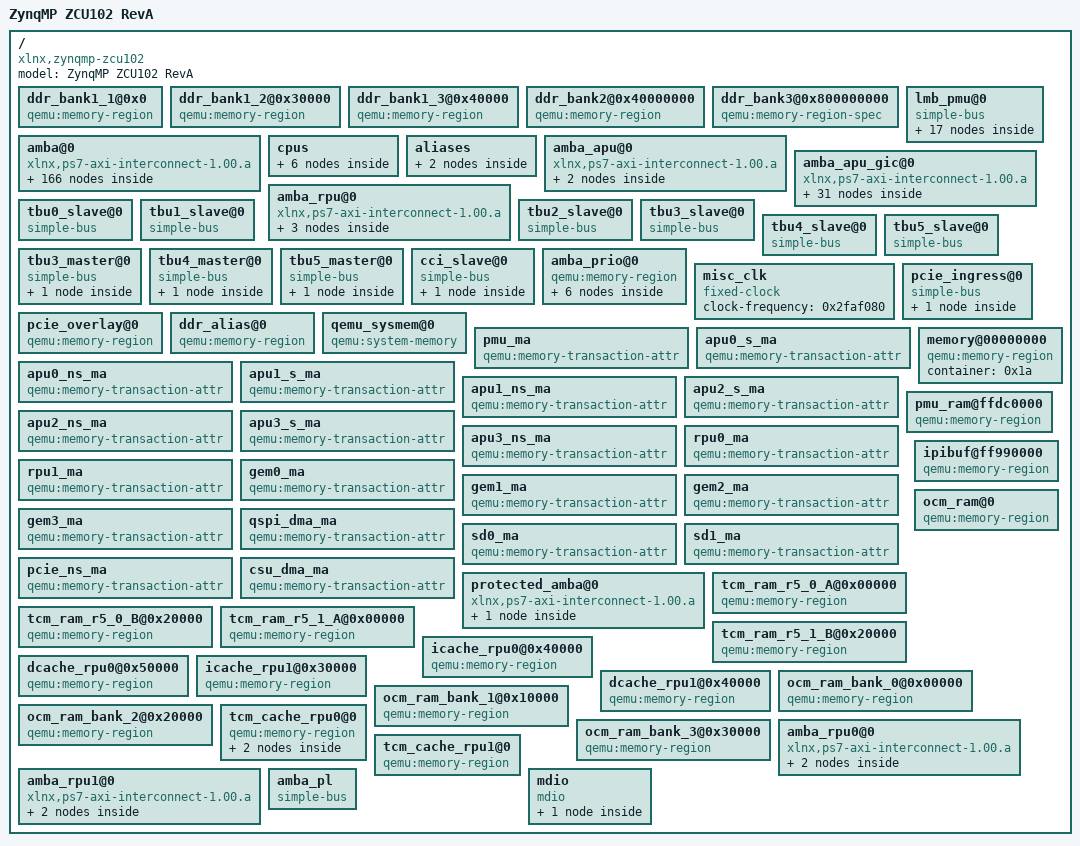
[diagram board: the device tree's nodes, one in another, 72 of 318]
/dts-v1/;

/ {
	#address-cells = <0x02>;
	#size-cells = <0x01>;
	model = "ZynqMP ZCU102 RevA";
	compatible = "xlnx,zynqmp-zcu102\0xlnx,zynqmp";

	ddr_bank1_1@0x0 {
		compatible = "qemu:memory-region";
		container = <0x01>;
		qemu,ram = <0x01>;
		reg = <0x00 0x00 0x30000>;
	};

	ddr_bank1_2@0x30000 {
		compatible = "qemu:memory-region";
		container = <0x01>;
		qemu,ram = <0x01>;
		reg = <0x00 0x30000 0x10000>;
		phandle = <0x74>;
	};

	ddr_bank1_3@0x40000 {
		compatible = "qemu:memory-region";
		container = <0x01>;
		qemu,ram = <0x01>;
		reg = <0x00 0x40000 0x3ffc0000>;
	};

	ddr_bank2@0x40000000 {
		compatible = "qemu:memory-region";
		container = <0x01>;
		qemu,ram = <0x01>;
		reg = <0x00 0x40000000 0x40000000>;
	};

	ddr_bank3@0x800000000 {
		compatible = "qemu:memory-region-spec";
		container = <0x01>;
		qemu,ram = <0x01>;
		reg = <0x08 0x00 0x08 0x00>;
	};

	amba@0 {
		#interrupt-cells = <0x01>;
		compatible = "xlnx,ps7-axi-interconnect-1.00.a\0simple-bus";
		ranges;
		interrupt-map-mask = <0x00 0x00 0xffff>;
		interrupt-map = <0x00 0x00 0x08 0x02 0x00 0x08 0x04 0x00 0x00 0x09 0x02 0x00 0x09 0x04 0x00 0x00 0x0a 0x02 0x00 0x0a 0x04 0x00 0x00 0x0b 0x02 0x00 0x0b 0x04 0x00 0x00 0x0b 0x02 0x00 0x0b 0x04 0x00 0x00 0x0b 0x02 0x00 0x0b 0x04 0x00 0x00 0x0b 0x02 0x00 0x0b 0x04 0x00 0x00 0x0b 0x02 0x00 0x0b 0x04 0x00 0x00 0x0b 0x02 0x00 0x0b 0x04 0x00 0x00 0x0b 0x02 0x00 0x0b 0x04 0x00 0x00 0x0b 0x02 0x00 0x0b 0x04 0x00 0x00 0x0b 0x02 0x00 0x0b 0x04 0x00 0x00 0x0b 0x02 0x00 0x0b 0x04 0x00 0x00 0x0b 0x02 0x00 0x0b 0x04 0x00 0x00 0x0b 0x02 0x00 0x0b 0x04 0x00 0x00 0x0b 0x02 0x00 0x0b 0x04 0x00 0x00 0x0b 0x02 0x00 0x0b 0x04 0x00 0x00 0x0c 0x02 0x00 0x0c 0x04 0x00 0x00 0x0d 0x02 0x00 0x0d 0x04 0x00 0x00 0x0e 0x02 0x00 0x0e 0x04 0x00 0x00 0x0f 0x02 0x00 0x0f 0x04 0x00 0x00 0x10 0x02 0x00 0x10 0x04 0x00 0x00 0x11 0x02 0x00 0x11 0x04 0x00 0x00 0x12 0x02 0x00 0x12 0x04 0x00 0x00 0x13 0x02 0x00 0x13 0x04 0x00 0x00 0x14 0x02 0x00 0x14 0x04 0x00 0x00 0x15 0x02 0x00 0x15 0x04 0x00 0x00 0x16 0x02 0x00 0x16 0x04 0x00 0x00 0x17 0x02 0x00 0x17 0x04 0x00 0x00 0x18 0x02 0x00 0x18 0x04 0x00 0x00 0x19 0x02 0x00 0x19 0x04 0x00 0x00 0x19 0x02 0x00 0x19 0x04 0x00 0x00 0x1a 0x02 0x00 0x1a 0x04 0x00 0x00 0x1b 0x02 0x00 0x1b 0x04 0x00 0x00 0x1c 0x02 0x00 0x1c 0x04 0x00 0x00 0x1d 0x02 0x00 0x1d 0x04 0x00 0x00 0x1e 0x02 0x00 0x1e 0x04 0x00 0x00 0x1f 0x02 0x00 0x1f 0x04 0x00 0x00 0x20 0x02 0x00 0x20 0x04 0x00 0x00 0x21 0x02 0x00 0x21 0x04 0x00 0x00 0x22 0x02 0x00 0x22 0x04 0x00 0x00 0x23 0x02 0x00 0x23 0x04 0x00 0x00 0x24 0x02 0x00 0x24 0x04 0x00 0x00 0x25 0x02 0x00 0x25 0x04 0x00 0x00 0x26 0x02 0x00 0x26 0x04 0x00 0x00 0x27 0x02 0x00 0x27 0x04 0x00 0x00 0x28 0x02 0x00 0x28 0x04 0x00 0x00 0x29 0x02 0x00 0x29 0x04 0x00 0x00 0x2a 0x02 0x00 0x2a 0x04 0x00 0x00 0x2b 0x02 0x00 0x2b 0x04 0x00 0x00 0x2c 0x02 0x00 0x2c 0x04 0x00 0x00 0x2d 0x02 0x00 0x2d 0x04 0x00 0x00 0x2e 0x02 0x00 0x2e 0x04 0x00 0x00 0x2f 0x02 0x00 0x2f 0x04 0x00 0x00 0x30 0x02 0x00 0x30 0x04 0x00 0x00 0x31 0x02 0x00 0x31 0x04 0x00 0x00 0x32 0x02 0x00 0x32 0x04 0x00 0x00 0x33 0x02 0x00 0x33 0x04 0x00 0x00 0x34 0x02 0x00 0x34 0x04 0x00 0x00 0x35 0x02 0x00 0x35 0x04 0x00 0x00 0x36 0x02 0x00 0x36 0x04 0x00 0x00 0x37 0x02 0x00 0x37 0x04 0x00 0x00 0x38 0x02 0x00 0x38 0x04 0x00 0x00 0x39 0x02 0x00 0x39 0x04 0x00 0x00 0x3a 0x02 0x00 0x3a 0x04 0x00 0x00 0x3b 0x02 0x00 0x3b 0x04 0x00 0x00 0x3c 0x02 0x00 0x3c 0x04 0x00 0x00 0x3d 0x02 0x00 0x3d 0x04 0x00 0x00 0x3e 0x02 0x00 0x3e 0x04 0x00 0x00 0x3f 0x02 0x00 0x3f 0x04 0x00 0x00 0x40 0x02 0x00 0x40 0x04 0x00 0x00 0x41 0x02 0x00 0x41 0x04 0x00 0x00 0x42 0x02 0x00 0x42 0x04 0x00 0x00 0x43 0x02 0x00 0x43 0x04 0x00 0x00 0x44 0x02 0x00 0x44 0x04 0x00 0x00 0x45 0x02 0x00 0x45 0x04 0x00 0x00 0x46 0x02 0x00 0x46 0x04 0x00 0x00 0x47 0x02 0x00 0x47 0x04 0x00 0x00 0x48 0x02 0x00 0x48 0x04 0x00 0x00 0x49 0x02 0x00 0x49 0x04 0x00 0x00 0x4a 0x02 0x00 0x4a 0x04 0x00 0x00 0x4b 0x02 0x00 0x4b 0x04 0x00 0x00 0x4c 0x02 0x00 0x4c 0x04 0x00 0x00 0x4d 0x02 0x00 0x4d 0x04 0x00 0x00 0x4e 0x02 0x00 0x4e 0x04 0x00 0x00 0x4f 0x02 0x00 0x4f 0x04 0x00 0x00 0x50 0x02 0x00 0x50 0x04 0x00 0x00 0x51 0x02 0x00 0x51 0x04 0x00 0x00 0x52 0x02 0x00 0x52 0x04 0x00 0x00 0x53 0x02 0x00 0x53 0x04 0x00 0x00 0x54 0x02 0x00 0x54 0x04 0x00 0x00 0x55 0x02 0x00 0x55 0x04 0x00 0x00 0x56 0x02 0x00 0x56 0x04 0x00 0x00 0x57 0x02 0x00 0x57 0x04 0x00 0x00 0x58 0x02 0x00 0x58 0x04 0x00 0x00 0x58 0x02 0x00 0x58 0x04 0x00 0x00 0x59 0x02 0x00 0x59 0x04 0x00 0x00 0x5a 0x02 0x00 0x5a 0x04 0x00 0x00 0x5b 0x02 0x00 0x5b 0x04 0x00 0x00 0x5c 0x02 0x00 0x5c 0x04 0x00 0x00 0x5d 0x02 0x00 0x5d 0x04 0x00 0x00 0x5e 0x02 0x00 0x5e 0x04 0x00 0x00 0x5f 0x02 0x00 0x5f 0x04 0x00 0x00 0x60 0x02 0x00 0x60 0x04 0x00 0x00 0x68 0x02 0x00 0x68 0x04 0x00 0x00 0x69 0x02 0x00 0x69 0x04 0x00 0x00 0x6a 0x02 0x00 0x6a 0x04 0x00 0x00 0x6b 0x02 0x00 0x6b 0x04 0x00 0x00 0x6c 0x02 0x00 0x6c 0x04 0x00 0x00 0x6d 0x02 0x00 0x6d 0x04 0x00 0x00 0x6e 0x02 0x00 0x6e 0x04 0x00 0x00 0x6f 0x02 0x00 0x6f 0x04 0x00 0x00 0x70 0x02 0x00 0x70 0x04 0x00 0x00 0x71 0x02 0x00 0x71 0x04 0x00 0x00 0x72 0x02 0x00 0x72 0x04 0x00 0x00 0x73 0x02 0x00 0x73 0x04 0x00 0x00 0x74 0x02 0x00 0x74 0x04 0x00 0x00 0x75 0x02 0x00 0x75 0x04 0x00 0x00 0x76 0x02 0x00 0x76 0x04 0x00 0x00 0x77 0x02 0x00 0x77 0x04 0x00 0x00 0x78 0x02 0x00 0x78 0x04 0x00 0x00 0x78 0x02 0x00 0x78 0x04 0x00 0x00 0x78 0x02 0x00 0x78 0x04 0x00 0x00 0x78 0x02 0x00 0x78 0x04 0x00 0x00 0x78 0x02 0x00 0x78 0x04 0x00 0x00 0x78 0x02 0x00 0x78 0x04 0x00 0x00 0x78 0x02 0x00 0x78 0x04 0x00 0x00 0x78 0x02 0x00 0x78 0x04 0x00 0x00 0x78 0x02 0x00 0x78 0x04 0x00 0x00 0x78 0x02 0x00 0x78 0x04 0x00 0x00 0x78 0x02 0x00 0x78 0x04 0x00 0x00 0x79 0x02 0x00 0x79 0x04 0x00 0x00 0x7a 0x02 0x00 0x7a 0x04 0x00 0x00 0x7b 0x02 0x00 0x7b 0x04 0x00 0x00 0x7b 0x02 0x00 0x7b 0x04 0x00 0x00 0x7c 0x02 0x00 0x7c 0x04 0x00 0x00 0x7d 0x02 0x00 0x7d 0x04 0x00 0x00 0x7e 0x02 0x00 0x7e 0x04 0x00 0x00 0x7f 0x02 0x00 0x7f 0x04 0x00 0x00 0x80 0x02 0x00 0x80 0x04 0x00 0x00 0x81 0x02 0x00 0x81 0x04 0x00 0x00 0x82 0x02 0x00 0x82 0x04 0x00 0x00 0x83 0x02 0x00 0x83 0x04 0x00 0x00 0x84 0x02 0x00 0x84 0x04 0x00 0x00 0x85 0x02 0x00 0x85 0x04 0x00 0x00 0x86 0x02 0x00 0x86 0x04 0x00 0x00 0x86 0x02 0x00 0x86 0x04 0x00 0x00 0x86 0x02 0x00 0x86 0x04 0x00 0x00 0x86 0x02 0x00 0x86 0x04 0x00 0x00 0x86 0x02 0x00 0x86 0x04 0x00 0x00 0x86 0x02 0x00 0x86 0x04 0x00 0x00 0x86 0x02 0x00 0x86 0x04 0x00 0x00 0x87 0x02 0x00 0x87 0x04 0x00 0x00 0x88 0x02 0x00 0x88 0x04 0x00 0x00 0x89 0x02 0x00 0x89 0x04 0x00 0x00 0x8a 0x02 0x00 0x8a 0x04 0x00 0x00 0x8b 0x02 0x00 0x8b 0x04 0x00 0x00 0x8c 0x02 0x00 0x8c 0x04 0x00 0x00 0x8d 0x02 0x00 0x8d 0x04 0x00 0x00 0x8e 0x02 0x00 0x8e 0x04 0x00 0x00 0x8f 0x02 0x00 0x8f 0x04 0x00 0x00 0x90 0x02 0x00 0x90 0x04 0x00 0x00 0x91 0x02 0x00 0x91 0x04 0x00 0x00 0x92 0x02 0x00 0x92 0x04 0x00 0x00 0x93 0x02 0x00 0x93 0x04 0x00 0x00 0x94 0x02 0x00 0x94 0x04 0x00 0x00 0x95 0x02 0x00 0x95 0x04 0x00 0x00 0x96 0x02 0x00 0x96 0x04 0x00 0x00 0x97 0x02 0x00 0x97 0x04 0x00 0x00 0x98 0x02 0x00 0x98 0x04 0x00 0x00 0x99 0x02 0x00 0x99 0x04 0x00 0x00 0x9a 0x02 0x00 0x9a 0x04 0x00 0x00 0x9b 0x02 0x00 0x9b 0x04 0x00 0x00 0x08 0x03 0x00 0x08 0x04 0x00 0x00 0x09 0x03 0x00 0x09 0x04 0x00 0x00 0x0a 0x03 0x00 0x0a 0x04 0x00 0x00 0x0b 0x03 0x00 0x0b 0x04 0x00 0x00 0x0b 0x03 0x00 0x0b 0x04 0x00 0x00 0x0b 0x03 0x00 0x0b 0x04 0x00 0x00 0x0b 0x03 0x00 0x0b 0x04 0x00 0x00 0x0b 0x03 0x00 0x0b 0x04 0x00 0x00 0x0b 0x03 0x00 0x0b 0x04 0x00 0x00 0x0b 0x03 0x00 0x0b 0x04 0x00 0x00 0x0b 0x03 0x00 0x0b 0x04 0x00 0x00 0x0b 0x03 0x00 0x0b 0x04 0x00 0x00 0x0b 0x03 0x00 0x0b 0x04 0x00 0x00 0x0b 0x03 0x00 0x0b 0x04 0x00 0x00 0x0b 0x03 0x00 0x0b 0x04 0x00 0x00 0x0b 0x03 0x00 0x0b 0x04 0x00 0x00 0x0b 0x03 0x00 0x0b 0x04 0x00 0x00 0x0c 0x03 0x00 0x0c 0x04 0x00 0x00 0x0d 0x03 0x00 0x0d 0x04 0x00 0x00 0x0e 0x03 0x00 0x0e 0x04 0x00 0x00 0x0f 0x03 0x00 0x0f 0x04 0x00 0x00 0x10 0x03 0x00 0x10 0x04 0x00 0x00 0x11 0x03 0x00 0x11 0x04 0x00 0x00 0x12 0x03 0x00 0x12 0x04 0x00 0x00 0x13 0x03 0x00 0x13 0x04 0x00 0x00 0x14 0x03 0x00 0x14 0x04 0x00 0x00 0x15 0x03 0x00 0x15 0x04 0x00 0x00 0x16 0x03 0x00 0x16 0x04 0x00 0x00 0x17 0x03 0x00 0x17 0x04 0x00 0x00 0x18 0x03 0x00 0x18 0x04 0x00 0x00 0x19 0x03 0x00 0x19 0x04 0x00 0x00 0x19 0x03 0x00 0x19 0x04 0x00 0x00 0x1a 0x03 0x00 0x1a 0x04 0x00 0x00 0x1b 0x03 0x00 0x1b 0x04 0x00 0x00 0x1c 0x03 0x00 0x1c 0x04 0x00 0x00 0x1d 0x03 0x00 0x1d 0x04 0x00 0x00 0x1e 0x03 0x00 0x1e 0x04 0x00 0x00 0x1f 0x03 0x00 0x1f 0x04 0x00 0x00 0x20 0x03 0x00 0x20 0x04 0x00 0x00 0x21 0x03 0x00 0x21 0x04 0x00 0x00 0x22 0x03 0x00 0x22 0x04 0x00 0x00 0x23 0x03 0x00 0x23 0x04 0x00 0x00 0x24 0x03 0x00 0x24 0x04 0x00 0x00 0x25 0x03 0x00 0x25 0x04 0x00 0x00 0x26 0x03 0x00 0x26 0x04 0x00 0x00 0x27 0x03 0x00 0x27 0x04 0x00 0x00 0x28 0x03 0x00 0x28 0x04 0x00 0x00 0x29 0x03 0x00 0x29 0x04 0x00 0x00 0x2a 0x03 0x00 0x2a 0x04 0x00 0x00 0x2b 0x03 0x00 0x2b 0x04 0x00 0x00 0x2c 0x03 0x00 0x2c 0x04 0x00 0x00 0x2d 0x03 0x00 0x2d 0x04 0x00 0x00 0x2e 0x03 0x00 0x2e 0x04 0x00 0x00 0x2f 0x03 0x00 0x2f 0x04 0x00 0x00 0x30 0x03 0x00 0x30 0x04 0x00 0x00 0x31 0x03 0x00 0x31 0x04 0x00 0x00 0x32 0x03 0x00 0x32 0x04 0x00 0x00 0x33 0x03 0x00 0x33 0x04 0x00 0x00 0x34 0x03 0x00 0x34 0x04 0x00 0x00 0x35 0x03 0x00 0x35 0x04 0x00 0x00 0x36 0x03 0x00 0x36 0x04 0x00 0x00 0x37 0x03 0x00 0x37 0x04 0x00 0x00 0x38 0x03 0x00 0x38 0x04 0x00 0x00 0x39 0x03 0x00 0x39 0x04 0x00 0x00 0x3a 0x03 0x00 0x3a 0x04 0x00 0x00 0x3b 0x03 0x00 0x3b 0x04 0x00 0x00 0x3c 0x03 0x00 0x3c 0x04 0x00 0x00 0x3d 0x03 0x00 0x3d 0x04 0x00 0x00 0x3e 0x03 0x00 0x3e 0x04 0x00 0x00 0x3f 0x03 0x00 0x3f 0x04 0x00 0x00 0x40 0x03 0x00 0x40 0x04 0x00 0x00 0x41 0x03 0x00 0x41 0x04 0x00 0x00 0x42 0x03 0x00 0x42 0x04 0x00 0x00 0x43 0x03 0x00 0x43 0x04 0x00 0x00 0x44 0x03 0x00 0x44 0x04 0x00 0x00 0x45 0x03 0x00 0x45 0x04 0x00 0x00 0x46 0x03 0x00 0x46 0x04 0x00 0x00 0x47 0x03 0x00 0x47 0x04 0x00 0x00 0x48 0x03 0x00 0x48 0x04 0x00 0x00 0x49 0x03 0x00 0x49 0x04 0x00 0x00 0x4a 0x03 0x00 0x4a 0x04 0x00 0x00 0x4b 0x03 0x00 0x4b 0x04 0x00 0x00 0x4c 0x03 0x00 0x4c 0x04 0x00 0x00 0x4d 0x03 0x00 0x4d 0x04 0x00 0x00 0x4e 0x03 0x00 0x4e 0x04 0x00 0x00 0x4f 0x03 0x00 0x4f 0x04 0x00 0x00 0x50 0x03 0x00 0x50 0x04 0x00 0x00 0x51 0x03 0x00 0x51 0x04 0x00 0x00 0x52 0x03 0x00 0x52 0x04 0x00 0x00 0x53 0x03 0x00 0x53 0x04 0x00 0x00 0x54 0x03 0x00 0x54 0x04 0x00 0x00 0x55 0x03 0x00 0x55 0x04 0x00 0x00 0x56 0x03 0x00 0x56 0x04 0x00 0x00 0x57 0x03 0x00 0x57 0x04 0x00 0x00 0x58 0x03 0x00 0x58 0x04 0x00 0x00 0x58 0x03 0x00 0x58 0x04 0x00 0x00 0x59 0x03 0x00 0x59 0x04 0x00 0x00 0x5a 0x03 0x00 0x5a 0x04 0x00 0x00 0x5b 0x03 0x00 0x5b 0x04 0x00 0x00 0x5c 0x03 0x00 0x5c 0x04 0x00 0x00 0x5d 0x03 0x00 0x5d 0x04 0x00 0x00 0x5e 0x03 0x00 0x5e 0x04 0x00 0x00 0x5f 0x03 0x00 0x5f 0x04 0x00 0x00 0x60 0x03 0x00 0x60 0x04 0x00 0x00 0x68 0x03 0x00 0x68 0x04 0x00 0x00 0x69 0x03 0x00 0x69 0x04 0x00 0x00 0x6a 0x03 0x00 0x6a 0x04 0x00 0x00 0x6b 0x03 0x00 0x6b 0x04 0x00 0x00 0x6c 0x03 0x00 0x6c 0x04 0x00 0x00 0x6d 0x03 0x00 0x6d 0x04 0x00 0x00 0x6e 0x03 0x00 0x6e 0x04 0x00 0x00 0x6f 0x03 0x00 0x6f 0x04 0x00 0x00 0x70 0x03 0x00 0x70 0x04 0x00 0x00 0x71 0x03 0x00 0x71 0x04 0x00 0x00 0x72 0x03 0x00 0x72 0x04 0x00 0x00 0x73 0x03 0x00 0x73 0x04 0x00 0x00 0x74 0x03 0x00 0x74 0x04 0x00 0x00 0x75 0x03 0x00 0x75 0x04 0x00 0x00 0x76 0x03 0x00 0x76 0x04 0x00 0x00 0x77 0x03 0x00 0x77 0x04 0x00 0x00 0x78 0x03 0x00 0x78 0x04 0x00 0x00 0x78 0x03 0x00 0x78 0x04 0x00 0x00 0x78 0x03 0x00 0x78 0x04 0x00 0x00 0x78 0x03 0x00 0x78 0x04 0x00 0x00 0x78 0x03 0x00 0x78 0x04 0x00 0x00 0x78 0x03 0x00 0x78 0x04 0x00 0x00 0x78 0x03 0x00 0x78 0x04 0x00 0x00 0x78 0x03 0x00 0x78 0x04 0x00 0x00 0x78 0x03 0x00 0x78 0x04 0x00 0x00 0x78 0x03 0x00 0x78 0x04 0x00 0x00 0x78 0x03 0x00 0x78 0x04 0x00 0x00 0x79 0x03 0x00 0x79 0x04 0x00 0x00 0x7a 0x03 0x00 0x7a 0x04 0x00 0x00 0x7b 0x03 0x00 0x7b 0x04 0x00 0x00 0x7b 0x03 0x00 0x7b 0x04 0x00 0x00 0x7c 0x03 0x00 0x7c 0x04 0x00 0x00 0x7d 0x03 0x00 0x7d 0x04 0x00 0x00 0x7e 0x03 0x00 0x7e 0x04 0x00 0x00 0x7f 0x03 0x00 0x7f 0x04 0x00 0x00 0x80 0x03 0x00 0x80 0x04 0x00 0x00 0x81 0x03 0x00 0x81 0x04 0x00 0x00 0x82 0x03 0x00 0x82 0x04 0x00 0x00 0x83 0x03 0x00 0x83 0x04 0x00 0x00 0x84 0x03 0x00 0x84 0x04 0x00 0x00 0x85 0x03 0x00 0x85 0x04 0x00 0x00 0x86 0x03 0x00 0x86 0x04 0x00 0x00 0x86 0x03 0x00 0x86 0x04 0x00 0x00 0x86 0x03 0x00 0x86 0x04 0x00 0x00 0x86 0x03 0x00 0x86 0x04 0x00 0x00 0x86 0x03 0x00 0x86 0x04 0x00 0x00 0x86 0x03 0x00 0x86 0x04 0x00 0x00 0x86 0x03 0x00 0x86 0x04 0x00 0x00 0x87 0x03 0x00 0x87 0x04 0x00 0x00 0x88 0x03 0x00 0x88 0x04 0x00 0x00 0x89 0x03 0x00 0x89 0x04 0x00 0x00 0x8a 0x03 0x00 0x8a 0x04 0x00 0x00 0x8b 0x03 0x00 0x8b 0x04 0x00 0x00 0x8c 0x03 0x00 0x8c 0x04 0x00 0x00 0x8d 0x03 0x00 0x8d 0x04 0x00 0x00 0x8e 0x03 0x00 0x8e 0x04 0x00 0x00 0x8f 0x03 0x00 0x8f 0x04 0x00 0x00 0x90 0x03 0x00 0x90 0x04 0x00 0x00 0x91 0x03 0x00 0x91 0x04 0x00 0x00 0x92 0x03 0x00 0x92 0x04 0x00 0x00 0x93 0x03 0x00 0x93 0x04 0x00 0x00 0x94 0x03 0x00 0x94 0x04 0x00 0x00 0x95 0x03 0x00 0x95 0x04 0x00 0x00 0x96 0x03 0x00 0x96 0x04 0x00 0x00 0x97 0x03 0x00 0x97 0x04 0x00 0x00 0x98 0x03 0x00 0x98 0x04 0x00 0x00 0x99 0x03 0x00 0x99 0x04 0x00 0x00 0x9a 0x03 0x00 0x9a 0x04 0x00 0x00 0x9b 0x03 0x00 0x9b 0x04>;
		#address-cells = <0x02>;
		#size-cells = <0x01>;
		phandle = <0x1a>;

		apu@0xFD5C0000 {
			compatible = "xlnx,apu";
			#gpio-cells = <0x01>;
			reg = <0x00 0xfd5c0000 0x1000>;
			cpu0 = <0x04>;
			cpu1 = <0x05>;
			cpu2 = <0x06>;
			cpu3 = <0x07>;
		};

		rpu_control@0xFF9A0000 {
			#gpio-cells = <0x01>;
			compatible = "xlnx,rpu-control";
			reg = <0x00 0xff9a0000 0x400>;
			gpio-controller;
			atcm1-for-rpu0 = <0x08>;
			btcm1-for-rpu0 = <0x09>;
			icache-for-rpu1 = <0x0a>;
			dcache-for-rpu1 = <0x0b>;
			gic-for-rpu = <0x03>;
			gpios = <0x0c 0x06 0x0c 0x07>;
			ddr-mem-for-rpu = <0x0d>;
			phandle = <0x6c>;
		};

		pmu_global@0xFFD80000 {
			interrupt-parent = <0x0e>;
			interrupts = <0x17 0x00 0x18 0x00 0x1a 0x00 0x1b 0x00 0x1c 0x00 0x1d 0x00>;
			compatible = "xlnx,pmu_global";
			reg = <0x00 0xffd80000 0x40000>;
			gpio-controller;
			#gpio-cells = <0x01>;
			num-gpios = <0x1a>;
			ignore-pwr-req = <0x01>;
			phandle = <0x0c>;
		};

		apu_ipi@0xFF300000 {
			compatible = "xlnx,zynqmp_ipi";
			gpio-controller;
			#gpio-cells = <0x02>;
			interrupts = <0x00>;
			interrupt-map = <0x00 0x00 0x00 0x02 0x00 0x23 0x04 0x00 0x00 0x00 0x03 0x00 0x23 0x04>;
			interrupt-map-mask = <0x00 0x00 0x00 0x00>;
			reg = <0x00 0xff300000 0x1000>;
			num-gpios = <0x40>;
			interrupt-gpios = <0x0f 0x00 0x00 0x10 0x00 0x00 0x11 0x00 0x00 0x12 0x00 0x00 0x13 0x00 0x00 0x14 0x00 0x00 0x15 0x00 0x00 0x16 0x00 0x00 0x17 0x00 0x00 0x18 0x00 0x00 0x19 0x00 0x00>;
			gpios = <0x0f 0x20 0x00 0x10 0x20 0x00 0x11 0x20 0x00 0x12 0x20 0x00 0x13 0x20 0x00 0x14 0x20 0x00 0x15 0x20 0x00 0x16 0x20 0x00 0x17 0x20 0x00 0x18 0x20 0x00 0x19 0x20 0x00>;
			phandle = <0x0f>;
		};

		rpu_0_ipi@0xFF310000 {
			compatible = "xlnx,zynqmp_ipi";
			gpio-controller;
			#gpio-cells = <0x02>;
			interrupts = <0x00>;
			interrupt-map = <0x00 0x00 0x00 0x02 0x00 0x21 0x04 0x00 0x00 0x00 0x03 0x00 0x21 0x04>;
			interrupt-map-mask = <0x00 0x00 0x00 0x00>;
			reg = <0x00 0xff310000 0x1000>;
			num-gpios = <0x40>;
			interrupt-gpios = <0x0f 0x08 0x00 0x10 0x08 0x00 0x11 0x08 0x00 0x12 0x08 0x00 0x13 0x08 0x00 0x14 0x08 0x00 0x15 0x08 0x00 0x16 0x08 0x00 0x17 0x08 0x00 0x18 0x08 0x00 0x19 0x08 0x00>;
			gpios = <0x0f 0x28 0x00 0x10 0x28 0x00 0x11 0x28 0x00 0x12 0x28 0x00 0x13 0x28 0x00 0x14 0x28 0x00 0x15 0x28 0x00 0x16 0x28 0x00 0x17 0x28 0x00 0x18 0x28 0x00 0x19 0x28 0x00>;
			phandle = <0x10>;
		};

		rpu_1_ipi@0xFF320000 {
			compatible = "xlnx,zynqmp_ipi";
			gpio-controller;
			#gpio-cells = <0x02>;
			interrupts = <0x00>;
			interrupt-map = <0x00 0x00 0x00 0x02 0x00 0x22 0x04 0x00 0x00 0x00 0x03 0x00 0x22 0x04>;
			interrupt-map-mask = <0x00 0x00 0x00 0x00>;
			reg = <0x00 0xff320000 0x1000>;
			num-gpios = <0x40>;
			interrupt-gpios = <0x0f 0x09 0x00 0x10 0x09 0x00 0x11 0x09 0x00 0x12 0x09 0x00 0x13 0x09 0x00 0x14 0x09 0x00 0x15 0x09 0x00 0x16 0x09 0x00 0x17 0x09 0x00 0x18 0x09 0x00 0x19 0x09 0x00>;
			gpios = <0x0f 0x29 0x00 0x10 0x29 0x00 0x11 0x29 0x00 0x12 0x29 0x00 0x13 0x29 0x00 0x14 0x29 0x00 0x15 0x29 0x00 0x16 0x29 0x00 0x17 0x29 0x00 0x18 0x29 0x00 0x19 0x29 0x00>;
			phandle = <0x11>;
		};

		pmu_0_ipi@0xFF330000 {
			compatible = "xlnx,zynqmp_ipi";
			gpio-controller;
			#gpio-cells = <0x02>;
			interrupt-parent = <0x0e>;
			interrupts = <0x13 0x00>;
			reg = <0x00 0xff330000 0x1000>;
			num-gpios = <0x40>;
			interrupt-gpios = <0x0f 0x10 0x00 0x10 0x10 0x00 0x11 0x10 0x00 0x12 0x10 0x00 0x13 0x10 0x00 0x14 0x10 0x00 0x15 0x10 0x00 0x16 0x10 0x00 0x17 0x10 0x00 0x18 0x10 0x00 0x19 0x10 0x00>;
			gpios = <0x0f 0x30 0x00 0x10 0x30 0x00 0x11 0x30 0x00 0x12 0x30 0x00 0x13 0x30 0x00 0x14 0x30 0x00 0x15 0x30 0x00 0x16 0x30 0x00 0x17 0x30 0x00 0x18 0x30 0x00 0x19 0x30 0x00>;
			phandle = <0x12>;
		};

		pmu_1_ipi@0xFF331000 {
			compatible = "xlnx,zynqmp_ipi";
			gpio-controller;
			#gpio-cells = <0x02>;
			interrupt-parent = <0x0e>;
			interrupts = <0x14 0x00>;
			reg = <0x00 0xff331000 0x1000>;
			num-gpios = <0x40>;
			interrupt-gpios = <0x0f 0x11 0x00 0x10 0x11 0x00 0x11 0x11 0x00 0x12 0x11 0x00 0x13 0x11 0x00 0x14 0x11 0x00 0x15 0x11 0x00 0x16 0x11 0x00 0x17 0x11 0x00 0x18 0x11 0x00 0x19 0x11 0x00>;
			gpios = <0x0f 0x31 0x00 0x10 0x31 0x00 0x11 0x31 0x00 0x12 0x31 0x00 0x13 0x31 0x00 0x14 0x31 0x00 0x15 0x31 0x00 0x16 0x31 0x00 0x17 0x31 0x00 0x18 0x31 0x00 0x19 0x31 0x00>;
			phandle = <0x13>;
		};

		pmu_2_ipi@0xFF332000 {
			compatible = "xlnx,zynqmp_ipi";
			gpio-controller;
			#gpio-cells = <0x02>;
			interrupt-parent = <0x0e>;
			interrupts = <0x15 0x00>;
			reg = <0x00 0xff332000 0x1000>;
			num-gpios = <0x40>;
			interrupt-gpios = <0x0f 0x12 0x00 0x10 0x12 0x00 0x11 0x12 0x00 0x12 0x12 0x00 0x13 0x12 0x00 0x14 0x12 0x00 0x15 0x12 0x00 0x16 0x12 0x00 0x17 0x12 0x00 0x18 0x12 0x00 0x19 0x12 0x00>;
			gpios = <0x0f 0x32 0x00 0x10 0x32 0x00 0x11 0x32 0x00 0x12 0x32 0x00 0x13 0x32 0x00 0x14 0x32 0x00 0x15 0x32 0x00 0x16 0x32 0x00 0x17 0x32 0x00 0x18 0x32 0x00 0x19 0x32 0x00>;
			phandle = <0x14>;
		};

		pmu_3_ipi@0xFF333000 {
			compatible = "xlnx,zynqmp_ipi";
			gpio-controller;
			#gpio-cells = <0x02>;
			interrupt-parent = <0x0e>;
			interrupts = <0x16 0x00>;
			reg = <0x00 0xff333000 0x1000>;
			num-gpios = <0x40>;
			interrupt-gpios = <0x0f 0x13 0x00 0x10 0x13 0x00 0x11 0x13 0x00 0x12 0x13 0x00 0x13 0x13 0x00 0x14 0x13 0x00 0x15 0x13 0x00 0x16 0x13 0x00 0x17 0x13 0x00 0x18 0x13 0x00 0x19 0x13 0x00>;
			gpios = <0x0f 0x33 0x00 0x10 0x33 0x00 0x11 0x33 0x00 0x12 0x33 0x00 0x13 0x33 0x00 0x14 0x33 0x00 0x15 0x33 0x00 0x16 0x33 0x00 0x17 0x33 0x00 0x18 0x33 0x00 0x19 0x33 0x00>;
			phandle = <0x15>;
		};

		pl_0_ipi@0xFF340000 {
			compatible = "xlnx,zynqmp_ipi";
			gpio-controller;
			#gpio-cells = <0x02>;
			interrupts = <0x00>;
			interrupt-map = <0x00 0x00 0x00 0x02 0x00 0x1d 0x04 0x00 0x00 0x00 0x03 0x00 0x1d 0x04>;
			interrupt-map-mask = <0x00 0x00 0x00 0x00>;
			reg = <0x00 0xff340000 0x1000>;
			num-gpios = <0x40>;
			interrupt-gpios = <0x0f 0x18 0x00 0x10 0x18 0x00 0x11 0x18 0x00 0x12 0x18 0x00 0x13 0x18 0x00 0x14 0x18 0x00 0x15 0x18 0x00 0x16 0x18 0x00 0x17 0x18 0x00 0x18 0x18 0x00 0x19 0x18 0x00>;
			gpios = <0x0f 0x34 0x00 0x10 0x34 0x00 0x11 0x34 0x00 0x12 0x34 0x00 0x13 0x34 0x00 0x14 0x34 0x00 0x15 0x34 0x00 0x16 0x34 0x00 0x17 0x34 0x00 0x18 0x34 0x00 0x19 0x34 0x00>;
			phandle = <0x16>;
		};

		pl_1_ipi@0xFF350000 {
			compatible = "xlnx,zynqmp_ipi";
			gpio-controller;
			#gpio-cells = <0x02>;
			interrupts = <0x00>;
			interrupt-map = <0x00 0x00 0x00 0x02 0x00 0x1e 0x04 0x00 0x00 0x00 0x03 0x00 0x1e 0x04>;
			interrupt-map-mask = <0x00 0x00 0x00 0x00>;
			reg = <0x00 0xff350000 0x1000>;
			num-gpios = <0x40>;
			interrupt-gpios = <0x0f 0x19 0x00 0x10 0x19 0x00 0x11 0x19 0x00 0x12 0x19 0x00 0x13 0x19 0x00 0x14 0x19 0x00 0x15 0x19 0x00 0x16 0x19 0x00 0x17 0x19 0x00 0x18 0x19 0x00 0x19 0x19 0x00>;
			gpios = <0x0f 0x35 0x00 0x10 0x35 0x00 0x11 0x35 0x00 0x12 0x35 0x00 0x13 0x35 0x00 0x14 0x35 0x00 0x15 0x35 0x00 0x16 0x35 0x00 0x17 0x35 0x00 0x18 0x35 0x00 0x19 0x35 0x00>;
			phandle = <0x17>;
		};

		pl_2_ipi@0xFF360000 {
			compatible = "xlnx,zynqmp_ipi";
			gpio-controller;
			#gpio-cells = <0x02>;
			interrupts = <0x00>;
			interrupt-map = <0x00 0x00 0x00 0x02 0x00 0x1f 0x04 0x00 0x00 0x00 0x03 0x00 0x1f 0x04>;
			interrupt-map-mask = <0x00 0x00 0x00 0x00>;
			reg = <0x00 0xff360000 0x1000>;
			num-gpios = <0x40>;
			interrupt-gpios = <0x0f 0x1a 0x00 0x10 0x1a 0x00 0x11 0x1a 0x00 0x12 0x1a 0x00 0x13 0x1a 0x00 0x14 0x1a 0x00 0x15 0x1a 0x00 0x16 0x1a 0x00 0x17 0x1a 0x00 0x18 0x1a 0x00 0x19 0x1a 0x00>;
			gpios = <0x0f 0x36 0x00 0x10 0x36 0x00 0x11 0x36 0x00 0x12 0x36 0x00 0x13 0x36 0x00 0x14 0x36 0x00 0x15 0x36 0x00 0x16 0x36 0x00 0x17 0x36 0x00 0x18 0x36 0x00 0x19 0x36 0x00>;
			phandle = <0x18>;
		};

		pl_3_ipi@0xFF370000 {
			compatible = "xlnx,zynqmp_ipi";
			gpio-controller;
			#gpio-cells = <0x02>;
			interrupts = <0x00>;
			interrupt-map = <0x00 0x00 0x00 0x02 0x00 0x20 0x04 0x00 0x00 0x00 0x03 0x00 0x20 0x04>;
			interrupt-map-mask = <0x00 0x00 0x00 0x00>;
			reg = <0x00 0xff370000 0x1000>;
			num-gpios = <0x40>;
			interrupt-gpios = <0x0f 0x1b 0x00 0x10 0x1b 0x00 0x11 0x1b 0x00 0x12 0x1b 0x00 0x13 0x1b 0x00 0x14 0x1b 0x00 0x15 0x1b 0x00 0x16 0x1b 0x00 0x17 0x1b 0x00 0x18 0x1b 0x00 0x19 0x1b 0x00>;
			gpios = <0x0f 0x37 0x00 0x10 0x37 0x00 0x11 0x37 0x00 0x12 0x37 0x00 0x13 0x37 0x00 0x14 0x37 0x00 0x15 0x37 0x00 0x16 0x37 0x00 0x17 0x37 0x00 0x18 0x37 0x00 0x19 0x37 0x00>;
			phandle = <0x19>;
		};

		csu_core {
			compatible = "xlnx,zynqmp-csu-core";
			reg = <0x00 0xffca0000 0x100>;
			phandle = <0x58>;
		};

		zynqmp_lpd_slcr@0xFF410000 {
			compatible = "xlnx,lpd-slcr";
			reg = <0x00 0xff410000 0x9000>;
			gic-for-rpu = <0x03>;
			gic-for-apu = <0x02>;
		};

		zynqmp_lpd_slcr_secure@0xFF4B0000 {
			compatible = "xlnx,lpd-slcr-secure";
			reg = <0x00 0xff4b0000 0x38>;
		};

		xppu@0 {
			compatible = "xlnx,xppu";
			reg-extended = <0x1a 0x00 0xff980000 0x10000 0x1b 0x00 0xff990000 0x00 0x1000 0x03 0x1b 0x00 0xff000000 0x00 0xfc0000 0x02 0x1b 0x00 0xfe000000 0x00 0x1000000 0x02 0x1b 0x00 0xc0000000 0x00 0x20000000 0x02>;
			mr = <0x1a>;
			interrupts = <0x58>;
		};

		smmu0@0xFD800000 {
			compatible = "arm,mmu-500";
			reg-extended = <0x1a 0x00 0xfd800000 0x10000 0x1c 0x00 0x00 0xffffffff 0xffffffff 0x1d 0x00 0x00 0xffffffff 0xffffffff 0x1e 0x00 0x00 0xffffffff 0xffffffff 0x1f 0x00 0x00 0xffffffff 0xffffffff 0x20 0x00 0x00 0xffffffff 0xffffffff 0x21 0x00 0x00 0xffffffff 0xffffffff>;
			interrupt-parent = <0x22>;
			interrupts = <0x00 0x01 0x02 0x03 0x04 0x05 0x06 0x07 0x08 0x09 0x0a 0x0b 0x0c 0x0d 0x0e 0x0f 0x10 0x11>;
			dma = <0x23>;
			mr-0 = <0x23>;
			mr-1 = <0x23>;
			mr-2 = <0x23>;
			mr-3 = <0x24>;
			mr-4 = <0x25>;
			mr-5 = <0x26>;
		};

		smmu0@0xFD5F0000 {
			compatible = "xlnx,smmu-reg";
			reg = <0x00 0xfd5f0000 0x1000>;
			interrupt-controller;
			interrupts = <0x9b>;
			phandle = <0x22>;
		};

		cci_mem1@0 {
			#address-cells = <0x02>;
			#size-cells = <0x02>;
			#priority-cells = <0x01>;
			compatible = "simple-bus";
			ranges;
			phandle = <0x27>;
		};

		cci_mem2@0 {
			#address-cells = <0x02>;
			#size-cells = <0x02>;
			#priority-cells = <0x01>;
			compatible = "simple-bus";
			ranges;
			phandle = <0x28>;
		};

		cci@0xFD6E0000 {
			compatible = "arm,cci-400";
			gpio-controller;
			#gpio-cells = <0x01>;
			reg-extended = <0x1a 0x00 0xfd6e0000 0xf000 0x23 0x00 0x00 0xffffffff 0xffffffff 0x02>;
			M0 = <0x1b>;
			M1 = <0x27>;
			M2 = <0x28>;
			phandle = <0x2b>;
		};

		ocm_xmpu@0xFFA70000 {
			compatible = "xlnx,xmpu";
			interrupts = <0x58>;
			reg-extended = <0x1a 0x00 0xffa70000 0x1000 0x1a 0x00 0xfffc0000 0x40000>;
			protected-mr = <0x29>;
			mr-0 = <0x1a>;
			protected-base = <0xfffc0000>;
		};

		ddr_xmpu0_@_DDR_XMPU0_CFG {
			compatible = "xlnx,xmpu";
			interrupts = <0x86>;
			reg-extended = <0x1a 0x00 0xfd000000 0x1000 0x2a 0x00 0x00 0x00 0x80000000 0x00>;
			align = <0x01>;
			protected-mr = <0x01>;
			protected-base = <0x00>;
			mr-0 = <0x2a>;
		};

		ddr_xmpu1_@_DDR_XMPU1_CFG {
			compatible = "xlnx,xmpu";
			interrupts = <0x86>;
			reg-extended = <0x1a 0x00 0xfd010000 0x1000 0x27 0x00 0x00 0x00 0x80000000 0x00>;
			align = <0x01>;
			protected-mr = <0x01>;
			protected-base = <0x00>;
			mr-0 = <0x27>;
			gpios = <0x2b 0x00>;
		};

		ddr_xmpu2_@_DDR_XMPU2_CFG {
			compatible = "xlnx,xmpu";
			interrupts = <0x86>;
			reg-extended = <0x1a 0x00 0xfd020000 0x1000 0x28 0x00 0x00 0x00 0x80000000 0x00>;
			align = <0x01>;
			protected-mr = <0x01>;
			protected-base = <0x00>;
			mr-0 = <0x28>;
			gpios = <0x2b 0x01>;
		};

		ddr_xmpu3_@_DDR_XMPU3_CFG {
			compatible = "xlnx,xmpu";
			interrupts = <0x86>;
			reg-extended = <0x1a 0x00 0xfd030000 0x1000 0x24 0x00 0x00 0x00 0x80000000 0x00>;
			align = <0x01>;
			protected-mr = <0x01>;
			protected-base = <0x00>;
			mr-0 = <0x24>;
		};

		ddr_xmpu4_@_DDR_XMPU4_CFG {
			compatible = "xlnx,xmpu";
			interrupts = <0x86>;
			reg-extended = <0x1a 0x00 0xfd040000 0x1000 0x25 0x00 0x00 0x00 0x80000000 0x00>;
			align = <0x01>;
			protected-mr = <0x01>;
			protected-base = <0x00>;
			mr-0 = <0x25>;
		};

		ddr_xmpu5_@_DDR_XMPU5_CFG {
			compatible = "xlnx,xmpu";
			interrupts = <0x86>;
			reg-extended = <0x1a 0x00 0xfd050000 0x1000 0x26 0x00 0x00 0x00 0x80000000 0x00>;
			align = <0x01>;
			protected-mr = <0x01>;
			protected-base = <0x00>;
			mr-0 = <0x26>;
		};

		downstream_amba_priority_bus {
			compatible = "qemu:memory-region";
			alias = <0x2c>;
			reg = <0x00 0x00 0xffffffff>;
			priority = <0xffffffff>;
		};

		ps7-afi@0xFD360000 {
			compatible = "xlnx,ps7-afi-1.00.a";
			reg = <0x00 0xfd360000 0x1000>;
		};

		ps7-afi@0xFD370000 {
			compatible = "xlnx,ps7-afi-1.00.a";
			reg = <0x00 0xfd370000 0x1000>;
		};

		ps7-afi@0xFD380000 {
			compatible = "xlnx,ps7-afi-1.00.a";
			reg = <0x00 0xfd380000 0x1000>;
		};

		ps7-afi@0xFD390000 {
			compatible = "xlnx,ps7-afi-1.00.a";
			reg = <0x00 0xfd390000 0x1000>;
		};

		ps7-afi@0xFD3A0000 {
			compatible = "xlnx,ps7-afi-1.00.a";
			reg = <0x00 0xfd3a0000 0x1000>;
		};

		ps7-afi@0xFD3B0000 {
			compatible = "xlnx,ps7-afi-1.00.a";
			reg = <0x00 0xfd3b0000 0x1000>;
		};

		gdma0mr {
			#address-cells = <0x02>;
			#size-cells = <0x01>;
			compatible = "simple-bus";
			ranges;
		};

		gdma0mattr {
			compatible = "qemu:memory-transaction-attr";
			secure = <0x00>;
			requester-id = <0x14e8>;
			phandle = <0x2d>;
		};

		gdma0@0xFD500000 {
			compatible = "xlnx,zdma";
			reg = <0x00 0xfd500000 0x1000>;
			bus-width = <0x80>;
			interrupts = <0x7c>;
			#stream-id-cells = <0x01>;
			dma = <0x21>;
			memattr = <0x2d>;
		};

		gdma1mr {
			#address-cells = <0x02>;
			#size-cells = <0x01>;
			compatible = "simple-bus";
			ranges;
		};

		gdma1mattr {
			compatible = "qemu:memory-transaction-attr";
			secure = <0x00>;
			requester-id = <0x14e9>;
			phandle = <0x2e>;
		};

		gdma1@0xFD510000 {
			compatible = "xlnx,zdma";
			reg = <0x00 0xfd510000 0x1000>;
			bus-width = <0x80>;
			interrupts = <0x7d>;
			#stream-id-cells = <0x01>;
			dma = <0x21>;
			memattr = <0x2e>;
		};

		gdma2mr {
			#address-cells = <0x02>;
			#size-cells = <0x01>;
			compatible = "simple-bus";
			ranges;
		};

		gdma2mattr {
			compatible = "qemu:memory-transaction-attr";
			secure = <0x00>;
			requester-id = <0x14ea>;
			phandle = <0x2f>;
		};

		gdma2@0xFD520000 {
			compatible = "xlnx,zdma";
			reg = <0x00 0xfd520000 0x1000>;
			bus-width = <0x80>;
			interrupts = <0x7e>;
			#stream-id-cells = <0x01>;
			dma = <0x21>;
			memattr = <0x2f>;
		};

		gdma3mr {
			#address-cells = <0x02>;
			#size-cells = <0x01>;
			compatible = "simple-bus";
			ranges;
		};

		gdma3mattr {
			compatible = "qemu:memory-transaction-attr";
			secure = <0x00>;
			requester-id = <0x14eb>;
			phandle = <0x30>;
		};

		gdma3@0xFD530000 {
			compatible = "xlnx,zdma";
			reg = <0x00 0xfd530000 0x1000>;
			bus-width = <0x80>;
			interrupts = <0x7f>;
			#stream-id-cells = <0x01>;
			dma = <0x21>;
			memattr = <0x30>;
		};

		gdma4mr {
			#address-cells = <0x02>;
			#size-cells = <0x01>;
			compatible = "simple-bus";
			ranges;
		};

		gdma4mattr {
			compatible = "qemu:memory-transaction-attr";
			secure = <0x00>;
			requester-id = <0x14ec>;
			phandle = <0x31>;
		};

		gdma4@0xFD540000 {
			compatible = "xlnx,zdma";
			reg = <0x00 0xfd540000 0x1000>;
			bus-width = <0x80>;
			interrupts = <0x80>;
			#stream-id-cells = <0x01>;
			dma = <0x21>;
			memattr = <0x31>;
		};

		gdma5mr {
			#address-cells = <0x02>;
			#size-cells = <0x01>;
			compatible = "simple-bus";
			ranges;
		};

		gdma5mattr {
			compatible = "qemu:memory-transaction-attr";
			secure = <0x00>;
			requester-id = <0x14ed>;
			phandle = <0x32>;
		};

		gdma5@0xFD550000 {
			compatible = "xlnx,zdma";
			reg = <0x00 0xfd550000 0x1000>;
			bus-width = <0x80>;
			interrupts = <0x81>;
			#stream-id-cells = <0x01>;
			dma = <0x21>;
			memattr = <0x32>;
		};

		gdma6mr {
			#address-cells = <0x02>;
			#size-cells = <0x01>;
			compatible = "simple-bus";
			ranges;
		};

		gdma6mattr {
			compatible = "qemu:memory-transaction-attr";
			secure = <0x00>;
			requester-id = <0x14ee>;
			phandle = <0x33>;
		};

		gdma6@0xFD560000 {
			compatible = "xlnx,zdma";
			reg = <0x00 0xfd560000 0x1000>;
			bus-width = <0x80>;
			interrupts = <0x82>;
			#stream-id-cells = <0x01>;
			dma = <0x21>;
			memattr = <0x33>;
		};

		gdma7mr {
			#address-cells = <0x02>;
			#size-cells = <0x01>;
			compatible = "simple-bus";
			ranges;
		};

		gdma7mattr {
			compatible = "qemu:memory-transaction-attr";
			secure = <0x00>;
			requester-id = <0x14ef>;
			phandle = <0x34>;
		};

		gdma7@0xFD570000 {
			compatible = "xlnx,zdma";
			reg = <0x00 0xfd570000 0x1000>;
			bus-width = <0x80>;
			interrupts = <0x83>;
			#stream-id-cells = <0x01>;
			dma = <0x21>;
			memattr = <0x34>;
		};

		crf@0xFD1A0000 {
			compatible = "xlnx,zynqmp_crf";
			reg = <0x00 0xfd1a0000 0x110>;
			gpio-controller;
			#gpio-cells = <0x01>;
			phandle = <0x62>;
		};

		axidpdma@0xFD4C0000 {
			compatible = "xlnx,axi-dpdma-1.0";
			reg = <0x00 0xfd4c0000 0x1000>;
			clocks = <0x35>;
			clock-names = "axi_clk";
			xlnx,axi-clock-freq = <0xbebc200>;
			interrupts = <0x7a>;
			dma = <0x1b>;
			dma-channels = <0x06>;
			#dma-cells = <0x01>;
			phandle = <0x37>;

			dma-video0channel@fe4c0000 {
				compatible = "xlnx,video0";
			};

			dma-video1channel@fe4c0000 {
				compatible = "xlnx,video1";
			};

			dma-video2channel@fe4c0000 {
				compatible = "xlnx,video2";
			};

			dma-graphicschannel@fe4c0000 {
				compatible = "xlnx,graphics";
			};

			dma-audio0channel@fe4c0000 {
				compatible = "xlnx,audio0";
			};

			dma-audio1channel@fe4c0000 {
				compatible = "xlnx,audio1";
			};
		};

		clock0 {
			compatible = "fixed-clock";
			#clock-cells = <0x00>;
			clock-frequency = <0x2faf080>;
			clock-accuracy = <0x64>;
			phandle = <0x36>;
		};

		clock1 {
			compatible = "dummy-clk";
			#clock-cells = <0x00>;
			clock-frequency = <0x2faf080>;
			phandle = <0x35>;
		};

		dp_sub@fd4aa000 {
			compatible = "xlnx,v-dp-sub-1.6";
			reg = <0x00 0xfd4aa000 0x4000>;
			xlnx,output-fmt = "rgb";
			phandle = <0x38>;
		};

		dp@0xFD4A0000 {
			compatible = "xlnx,v-dp-4.1";
			reg = <0x00 0xfd4a0000 0x1000>;
			interrupts = <0x77>;
			clock-names = "aclk";
			clocks = <0x36>;
			dpdma = <0x37>;
			xlnx,dp-version = "v1.2";
			xlnx,max-lanes = <0x02>;
			xlnx,max-link-rate = <0x278d0>;
			xlnx,max-bpc = <0x10>;
			xlnx,max-pclock = <0x7530>;
			xlnx,enable-ycrcb;
			xlnx,colormetry = "rgb";
			xlnx,bpc = <0x08>;
			xlnx,dp-sub = <0x38>;
			phandle = <0x39>;
		};

		xilinx_drm {
			compatible = "xlnx,drm";
			xlnx,encoder-slave = <0x39>;
			clocks = <0x35 0x00>;
			xlnx,connector-type = "DisplayPort";
			xlnx,dp-sub = <0x38>;

			planes {
				xlnx,pixel-format = "rgb565";

				plane0 {
					dmas = <0x37 0x03>;
					dma-names = "dma";
				};

				plane1 {
					dmas = <0x37 0x00>;
					dma-names = "dma";
				};
			};
		};

		ddr-phy@0xFD080000 {
			compatible = "xlnx,zynqmp-ddr-phy";
			reg = <0x00 0xfd080000 0x2000>;
		};

		memory-controller@0xFD070000 {
			compatible = "xlnx,zynqmp-ddrc";
			reg = <0x00 0xfd070000 0x1000>;
		};

		swdt@0xFF150000 {
			compatible = "xlnx,swdt";
			reg = <0x00 0xff150000 0x10>;
			interrupts = <0x34>;
			pclk = <0xf4240>;
			gpios = <0x0c 0x0c>;
		};

		wdt@0xFD4D0000 {
			compatible = "xlnx,swdt";
			reg = <0x00 0xfd4d0000 0x10>;
			interrupts = <0x71>;
			pclk = <0xf4240>;
			gpios = <0x0c 0x0d>;
		};

		csu_wdt@0xFFCB0000 {
			compatible = "xlnx,swdt";
			reg = <0x00 0xffcb0000 0x10>;
			interrupts = <0x35>;
			pclk = <0xf4240>;
		};

		zynqmp_iou_slcr@0xFF180000 {
			compatible = "xilinx,zynqmp-iou-slcr";
			reg = <0x00 0xff180000 0x1000>;
			gpio-controller;
			#gpio-cells = <0x02>;
			mio-bank0-1.8v = <0x01>;
			mio-bank1-1.8v = <0x01>;
			mio-bank2-1.8v = <0x01>;
			phandle = <0x44>;
		};

		ps7-can@0xFF060000 {
			compatible = "xlnx,zynqmp-can";
			interrupts = <0x17>;
			reg = <0x00 0xff060000 0x1000>;
			ctrl-idx = <0x00>;
		};

		ps7-can@0xFF070000 {
			compatible = "xlnx,zynqmp-can";
			interrupts = <0x18>;
			reg = <0x00 0xff070000 0x1000>;
			ctrl-idx = <0x01>;
		};

		serdes@0xFD400000 {
			compatible = "xlnx,zynqmp-serdes";
			reg = <0x00 0xfd400000 0x20000>;
		};

		gem0@0 {
			#address-cells = <0x01>;
			#size-cells = <0x00>;
			compatible = "cdns,gem";
			interrupts = <0x39 0x39>;
			dma = <0x1e>;
			memattr = <0x3a>;
			reg = <0x00 0xff0b0000 0x1000>;
			num-priority-queues = <0x02>;
			revision = <0x40070106>;
		};

		gem1@0 {
			#address-cells = <0x01>;
			#size-cells = <0x00>;
			compatible = "cdns,gem";
			interrupts = <0x3b 0x3b>;
			dma = <0x1e>;
			memattr = <0x3b>;
			reg = <0x00 0xff0c0000 0x1000>;
			num-priority-queues = <0x02>;
			revision = <0x40070106>;
		};

		gem2@0 {
			#address-cells = <0x01>;
			#size-cells = <0x00>;
			compatible = "cdns,gem";
			interrupts = <0x3d 0x3d>;
			dma = <0x1e>;
			memattr = <0x3c>;
			reg = <0x00 0xff0d0000 0x1000>;
			num-priority-queues = <0x02>;
			revision = <0x40070106>;
		};

		gem3@0 {
			#address-cells = <0x01>;
			#size-cells = <0x00>;
			compatible = "cdns,gem";
			interrupts = <0x3f 0x3f>;
			dma = <0x1e>;
			memattr = <0x3d>;
			reg = <0x00 0xff0e0000 0x1000>;
			num-priority-queues = <0x02>;
			revision = <0x40070106>;
			mdio = <0x3e>;
		};

		ahci@0xFD0C0000 {
			compatible = "generic-ahci\0sysbus-ahci";
			reg = <0x00 0xfd0c0000 0x2000>;
			interrupts = <0x85>;
			num-ports = <0x02>;
			dma = <0x1b>;
		};

		lpd_gpv@0xFE100000 {
			compatible = "xlnx,lpd-gpv";
			reg = <0x00 0xfe100000 0xc8130>;
		};

		usb3@0xFE200000 {
			compatible = "usb_dwc3";
			reg = <0x00 0xfe20c100 0x600 0x00 0xfe200000 0x4000>;
			interrupts = <0x41 0x42 0x43 0x44>;
			dma = <0x1a>;
		};

		usb3@0xFE300000 {
			compatible = "usb_dwc3";
			reg = <0x00 0xfe30c100 0x600 0x00 0xfe300000 0x4000>;
			interrupts = <0x46 0x47 0x48 0x49>;
			dma = <0x1a>;
		};

		arasan_nfc@0xFF100000 {
			compatible = "arasan,nfc";
			reg = <0x00 0xff100000 0x1000>;
			interrupts = <0x0e>;
			dma = <0x1b>;
			has-mdma = <0x01>;

			nand {
				#address-cells = <0x01>;
				#size-cells = <0x01>;

				partition@0 {
					label = "all";
					reg = <0x00 0x100000>;
				};
			};
		};

		psu_gpio@0xFF0A0000 {
			#gpio-cells = <0x01>;
			compatible = "xlnx,zynqmp-gpio";
			gpio-controller;
			interrupts = <0x10>;
			reg = <0x00 0xff0a0000 0x1000>;
		};

		csu_dma@0xFF0F0800 {
			compatible = "zynqmp,csu-dma";
			interrupts = <0x0f>;
			#stream-id-cells = <0x01>;
			reg = <0x00 0xff0f0800 0x800>;
			dma = <0x1e>;
			memattr = <0x3f>;
			is-dst = <0x01>;
			phandle = <0x40>;
		};

		ps7-qspi@0xFF0F0000 {
			#address-cells = <0x01>;
			#size-cells = <0x00>;
			#bus-cells = <0x01>;
			clock-names = "ref_clk\0pclk";
			compatible = "xlnx,usmp-gqspi\0cdns,spi-r1p6";
			stream-connected-dma = <0x40>;
			clocks = <0x41 0x41>;
			dma = <0x1b>;
			interrupts = <0x0f>;
			num-ss-bits = <0x02>;
			reg = <0x00 0xff0f0000 0x1000 0x00 0xc0000000 0x8000000>;
			speed-hz = <0x989680>;
			xlnx,fb-clk = <0x01>;
			xlnx,qspi-clk-freq-hz = <0xbebc200>;
			xlnx,qspi-mode = <0x02>;

			qspi_flash_lcs_lb@0 {
				#address-cells = <0x01>;
				#size-cells = <0x01>;
				#bus-cells = <0x01>;
				compatible = "n25q512a11\0st,m25p80";
				spi-max-frequency = <0x2faf080>;
				reg = <0x00 0x00>;

				qspi_flash_lcs_lb@0x00000000 {
					label = "qspi_flash_lcs_lb";
					reg = <0x00 0x2000000>;
				};
			};
		};

		sd_clk {
			#clock-cells = <0x00>;
			clock-frequency = <0x17d7840>;
			compatible = "fixed-clock";
			phandle = <0x42>;
		};

		ps7-sdio@0xFF160000 {
			clock-names = "ref_clk\0aper_clk";
			clock-frequency = <0x17d7840>;
			compatible = "xilinx,zynqmp-sdhci\0generic-sdhci";
			clocks = <0x42 0x42>;
			drive-index = <0x00>;
			interrupts = <0x30>;
			reg = <0x00 0xff160000 0x1000>;
			dma = <0x1e>;
			memattr = <0x43>;
			gpios = <0x44 0x00 0x00>;
			gpio-names = "SLOTTYPE";
			is-mmc = <0x00>;
			xlnx,has-cd = <0x01>;
			xlnx,has-power = <0x00>;
			xlnx,has-wp = <0x01>;
			xlnx,sdio-clk-freq-hz = <0x2faf080>;
		};

		ps7-sdio@0xFF170000 {
			clock-names = "ref_clk\0aper_clk";
			compatible = "xilinx,zynqmp-sdhci\0generic-sdhci";
			clocks = <0x41 0x41>;
			drive-index = <0x01>;
			interrupts = <0x31>;
			reg = <0x00 0xff170000 0x1000>;
			dma = <0x1e>;
			memattr = <0x45>;
			gpios = <0x44 0x01 0x00>;
			gpio-names = "SLOTTYPE";
			is-mmc = <0x01>;
			xlnx,has-cd = <0x01>;
			xlnx,has-power = <0x00>;
			xlnx,has-wp = <0x01>;
			xlnx,sdio-clk-freq-hz = <0x2faf080>;
		};

		ps7-spi@0xFF040000 {
			#address-cells = <0x01>;
			#size-cells = <0x00>;
			clock-names = "ref_clk\0pclk";
			clocks = <0x41 0x41>;
			compatible = "cdns,spi-r1p6";
			interrupts = <0x13>;
			num-ss-bits = <0x04>;
			reg = <0x00 0xff040000 0x1000>;
		};

		ps7-spi@0xFF050000 {
			#address-cells = <0x01>;
			#size-cells = <0x00>;
			clock-names = "ref_clk\0pclk";
			clocks = <0x41 0x41>;
			compatible = "cdns,spi-r1p6";
			interrupts = <0x14>;
			num-ss-bits = <0x04>;
			reg = <0x00 0xff050000 0x1000>;
		};

		ps7-ttc@0xFF110000 {
			clocks = <0x41>;
			compatible = "xlnx,ps7-ttc-1.00.a";
			interrupts = <0x24 0x25 0x26>;
			reg = <0x00 0xff110000 0x1000>;
			width = <0x20>;
		};

		ps7-ttc@0xFF120000 {
			clocks = <0x41>;
			compatible = "xlnx,ps7-ttc-1.00.a";
			interrupts = <0x27 0x28 0x29>;
			reg = <0x00 0xff120000 0x1000>;
			width = <0x20>;
		};

		ps7-ttc@0xFF130000 {
			clocks = <0x41>;
			compatible = "xlnx,ps7-ttc-1.00.a";
			interrupts = <0x2a 0x2b 0x2c>;
			reg = <0x00 0xff130000 0x1000>;
			width = <0x20>;
		};

		ps7-ttc@0xFF140000 {
			clocks = <0x41>;
			compatible = "xlnx,ps7-ttc-1.00.a";
			interrupts = <0x2d 0x2e 0x2f>;
			reg = <0x00 0xff140000 0x1000>;
			width = <0x20>;
		};

		uart_clk {
			#clock-cells = <0x00>;
			clock-frequency = <0x17d7840>;
			compatible = "fixed-clock";
			phandle = <0x46>;
		};

		serial@0xFF000000 {
			compatible = "xlnx,ps7-uart-1.00.a\0xlnx,xuartps";
			current-speed = <0x1c200>;
			interrupts = <0x15>;
			port-number = <0x01>;
			reg = <0x00 0xff000000 0x1000>;
			xlnx,has-modem = <0x00>;
			xlnx,uart-clk-freq-hz = <0x2faf080>;
			clock-names = "uart_clk\0pclk";
			clocks = <0x46 0x46>;
			ttrig-polarity = <0x01>;
		};

		serial@0xFF010000 {
			compatible = "xlnx,ps7-uart-1.00.a\0xlnx,xuartps";
			current-speed = <0x1c200>;
			interrupts = <0x16>;
			port-number = <0x00>;
			reg = <0x00 0xff010000 0x1000>;
			xlnx,has-modem = <0x00>;
			xlnx,uart-clk-freq-hz = <0x2faf080>;
			clock-names = "uart_clk\0pclk";
			clocks = <0x46 0x46>;
			ttrig-polarity = <0x01>;
			status = "disabled";
		};

		ocm_ctrl@0xFF960000 {
			compatible = "xlnx,zynqmp-ocmc";
			memsize = <0x40000>;
			reg = <0x00 0xff960000 0x1000>;
		};

		adma0mr {
			#address-cells = <0x02>;
			#size-cells = <0x01>;
			compatible = "simple-bus";
			ranges;
		};

		adma0mattr {
			compatible = "qemu:memory-transaction-attr";
			secure = <0x00>;
			requester-id = <0x868>;
			phandle = <0x47>;
		};

		adma0@0xFFA80000 {
			compatible = "xlnx,zdma";
			reg = <0x00 0xffa80000 0x1000>;
			bus-width = <0x40>;
			interrupts = <0x4d>;
			#stream-id-cells = <0x01>;
			dma = <0x1e>;
			memattr = <0x47>;
		};

		adma1mr {
			#address-cells = <0x02>;
			#size-cells = <0x01>;
			compatible = "simple-bus";
			ranges;
		};

		adma1mattr {
			compatible = "qemu:memory-transaction-attr";
			secure = <0x00>;
			requester-id = <0x869>;
			phandle = <0x48>;
		};

		adma1@0xFFA90000 {
			compatible = "xlnx,zdma";
			reg = <0x00 0xffa90000 0x1000>;
			bus-width = <0x40>;
			interrupts = <0x4e>;
			#stream-id-cells = <0x01>;
			dma = <0x1e>;
			memattr = <0x48>;
		};

		adma2mr {
			#address-cells = <0x02>;
			#size-cells = <0x01>;
			compatible = "simple-bus";
			ranges;
		};

		adma2mattr {
			compatible = "qemu:memory-transaction-attr";
			secure = <0x00>;
			requester-id = <0x86a>;
			phandle = <0x49>;
		};

		adma2@0xFFAA0000 {
			compatible = "xlnx,zdma";
			reg = <0x00 0xffaa0000 0x1000>;
			bus-width = <0x40>;
			interrupts = <0x4f>;
			#stream-id-cells = <0x01>;
			dma = <0x1e>;
			memattr = <0x49>;
		};

		adma3mr {
			#address-cells = <0x02>;
			#size-cells = <0x01>;
			compatible = "simple-bus";
			ranges;
		};

		adma3mattr {
			compatible = "qemu:memory-transaction-attr";
			secure = <0x00>;
			requester-id = <0x86b>;
			phandle = <0x4a>;
		};

		adma3@0xFFAB0000 {
			compatible = "xlnx,zdma";
			reg = <0x00 0xffab0000 0x1000>;
			bus-width = <0x40>;
			interrupts = <0x50>;
			#stream-id-cells = <0x01>;
			dma = <0x1e>;
			memattr = <0x4a>;
		};

		adma4mr {
			#address-cells = <0x02>;
			#size-cells = <0x01>;
			compatible = "simple-bus";
			ranges;
		};

		adma4mattr {
			compatible = "qemu:memory-transaction-attr";
			secure = <0x00>;
			requester-id = <0x86c>;
			phandle = <0x4b>;
		};

		adma4@0xFFAC0000 {
			compatible = "xlnx,zdma";
			reg = <0x00 0xffac0000 0x1000>;
			bus-width = <0x40>;
			interrupts = <0x51>;
			#stream-id-cells = <0x01>;
			dma = <0x1e>;
			memattr = <0x4b>;
		};

		adma5mr {
			#address-cells = <0x02>;
			#size-cells = <0x01>;
			compatible = "simple-bus";
			ranges;
		};

		adma5mattr {
			compatible = "qemu:memory-transaction-attr";
			secure = <0x00>;
			requester-id = <0x86d>;
			phandle = <0x4c>;
		};

		adma5@0xFFAD0000 {
			compatible = "xlnx,zdma";
			reg = <0x00 0xffad0000 0x1000>;
			bus-width = <0x40>;
			interrupts = <0x52>;
			#stream-id-cells = <0x01>;
			dma = <0x1e>;
			memattr = <0x4c>;
		};

		adma6mr {
			#address-cells = <0x02>;
			#size-cells = <0x01>;
			compatible = "simple-bus";
			ranges;
		};

		adma6mattr {
			compatible = "qemu:memory-transaction-attr";
			secure = <0x00>;
			requester-id = <0x86e>;
			phandle = <0x4d>;
		};

		adma6@0xFFAE0000 {
			compatible = "xlnx,zdma";
			reg = <0x00 0xffae0000 0x1000>;
			bus-width = <0x40>;
			interrupts = <0x53>;
			#stream-id-cells = <0x01>;
			dma = <0x1e>;
			memattr = <0x4d>;
		};

		adma7mr {
			#address-cells = <0x02>;
			#size-cells = <0x01>;
			compatible = "simple-bus";
			ranges;
		};

		adma7mattr {
			compatible = "qemu:memory-transaction-attr";
			secure = <0x00>;
			requester-id = <0x86f>;
			phandle = <0x4e>;
		};

		adma7@0xFFAF0000 {
			compatible = "xlnx,zdma";
			reg = <0x00 0xffaf0000 0x1000>;
			bus-width = <0x40>;
			interrupts = <0x54>;
			#stream-id-cells = <0x01>;
			dma = <0x1e>;
			memattr = <0x4e>;
		};

		crl@0xFF5E0000 {
			compatible = "xlnx,zynqmp-crl";
			reg = <0x00 0xff5e0000 0x1000>;
			gpio-controller;
			#gpio-cells = <0x01>;
			num-gpios = <0x03>;
			gpios = <0x0c 0x1a>;
			phandle = <0x4f>;
		};

		zynqmp_anms@0xFFA50000 {
			compatible = "xlnx,zynqmp_ams";
			reg = <0x00 0xffa50000 0x68>;
			gpio-controller;
			#gpio-cells = <0x02>;
		};

		zynqmp_sysmon_ps@0xFFA50800 {
			compatible = "xlnx,zynqmp_sysmon";
			reg = <0x00 0xffa50800 0x200>;
			gpio-controller;
			#gpio-cells = <0x02>;
		};

		zynqmp_sysmon_pl@0xFFA50C00 {
			compatible = "xlnx,zynqmp_sysmon";
			reg = <0x00 0xffa50c00 0x200>;
			gpio-controller;
			#gpio-cells = <0x02>;
		};

		zynqmp_rtc@0xFFA60000 {
			compatible = "xlnx-zynmp,rtc";
			interrupts = <0x0b 0x1a 0x1b>;
			reg = <0x00 0xffa60000 0x100>;
		};

		dummy_gpio@0 {
			gpio-controller;
			#gpio-cells = <0x01>;
		};

		cxtsgen@0xFF250000 {
			compatible = "arm,generic-timer";
			reg = <0x00 0xff260000 0x1000>;
		};

		ps_reset@0 {
			compatible = "qemu,reset-device";
			gpios = <0x4f 0x02 0x0c 0x03>;
		};

		pcie_attrib@0xFD480000 {
			compatible = "xlnx,nwl-pcie-attrib";
			reg = <0x00 0xfd480000 0x1000>;
			interrupts = <0x76>;
		};

		pcie_main@0xFD0E0000 {
			compatible = "xlnx,nwl-pcie-main";
			reg-extended = <0x1a 0x00 0xfd0e0000 0x1000 0x50 0x00 0xfe440000 0x00 0x1000 0x02 0x1a 0x80 0x00 0x10000000 0x51 0x00 0x00 0xffffffff 0xffffffff 0x00>;
			interrupts = <0x74 0x72 0x73>;
			dma = <0x50>;
			memattr = <0x52>;
		};

		zynqmp_boot@0 {
			compatible = "xlnx,zynqmp-boot";
			dma = <0x1a>;
		};

		rp_cosim_mio_in {
			gpio-controller;
			#gpio-cells = <0x02>;
			phandle = <0x5d>;
		};

		csu_dma_dst@0xFFC80800 {
			compatible = "zynqmp,csu-dma";
			interrupts = <0x56>;
			reg = <0x00 0xffc80800 0x800>;
			dma = <0x1b>;
			is-dst = <0x01>;
			memattr = <0x53>;
			phandle = <0x75>;
		};

		csu_dma_src@0xFFC80000 {
			compatible = "zynqmp,csu-dma";
			interrupts = <0x56>;
			stream-connected-dma = <0x54>;
			reg = <0x00 0xffc80000 0x800>;
			dma = <0x1b>;
			memattr = <0x53>;
		};

		csu_sha@0xFFCA2000 {
			compatible = "zynqmp,csu-sha3";
			reg = <0x00 0xffca2000 0x100>;
			phandle = <0x77>;
		};

		csu_aes@0xFFCA1000 {
			#gpio-cells = <0x01>;
			gpio-controller;
			compatible = "zynqmp,csu-aes";
			stream-connected-aes = <0x54>;
			reg = <0x00 0xffca1000 0x100>;
			gpios = <0x55 0x00 0x55 0x01>;
			gpio-names = "busy\0done";
			aes-core = <0x55>;
			phandle = <0x56>;

			xlnx_aes@0 {
				#gpio-cells = <0x01>;
				compatible = "xlnx-aes";
				gpios = <0x56 0x05>;
				gpio-names = "reset";
				phandle = <0x55>;
			};
		};

		csu_puf@0xFFCA4000 {
			compatible = "xlnx,zynqmp-pufop";
			zynqmp-aes-key-sink-puf = <0x56>;
			efuse = <0x57>;
			reg = <0x00 0xffca4000 0x1c>;
			puf-acc-err-sink = <0x58>;
		};

		csu_efuse@0xFFCC0000 {
			compatible = "xlnx,zynqmp-efuse";
			zynqmp-aes-key-sink-efuses = <0x56>;
			reg = <0x00 0xffcc0000 0x2000>;
			efuse = <0x57>;

			xlnx_efuse@0 {
				doc-ignore = <0x01>;
				compatible = "xlnx,efuse";
				efuse-nr = <0x03>;
				efuse-size = <0x800>;
				phandle = <0x57>;
			};
		};

		csu_bbram@0xFFCD0000 {
			compatible = "xlnx,bbram-ctrl";
			zynqmp-aes-key-sink-bbram = <0x56>;
			reg = <0x00 0xffcd0000 0x100>;
		};

		csu_rsa@0xFFCE0000 {
			compatible = "zynqmp,csu-rsa";
			reg = <0x00 0xffce0000 0x64>;
		};

		rpu0_for_main_bus {
			compatible = "qemu:memory-region";
			alias = <0x59>;
			reg = <0x00 0xffe00000 0x60000>;
		};

		rpu1_for_main_bus {
			compatible = "qemu:memory-region";
			alias = <0x5a>;
			reg = <0x00 0xffe90000 0x50000>;
		};

		i2c0@0xFF020000 {
			#address-cells = <0x01>;
			#size-cells = <0x00>;
			clocks = <0x41>;
			compatible = "xlnx,ps7-i2c-1.00.a\0cdns,i2c-r1p10";
			interrupts = <0x11>;
			reg = <0x00 0xff020000 0x1000>;
		};

		i2c1@0xFF030000 {
			#address-cells = <0x01>;
			#size-cells = <0x00>;
			clocks = <0x41>;
			compatible = "xlnx,ps7-i2c-1.00.a\0cdns,i2c-r1p10";
			interrupts = <0x12>;
			reg = <0x00 0xff030000 0x1000>;

			eeprom@50 {
				compatible = "at,24c08";
				reg = <0x50>;
				size = <0x2000>;
				blockdev-node-name = "i2c1.eeprom-50";
			};
		};
	};

	lmb_pmu@0 {
		#address-cells = <0x02>;
		#size-cells = <0x02>;
		#priority-cells = <0x01>;
		compatible = "simple-bus";
		ranges;
		phandle = <0x5b>;

		io-module@00 {
			#address-cells = <0x02>;
			#size-cells = <0x01>;
			#priority-cells = <0x00>;
			compatible = "xlnx,iomodule-1.02.a\0syscon\0simple-bus";
			container = <0x5b>;
			priority = <0x01>;
			xlnx,freq = <0x47868c0>;
			xlnx,instance = "iomodule_1";
			xlnx,io-mask = <0xfffe0000>;
			xlnx,lmb-awidth = <0x20>;
			xlnx,lmb-dwidth = <0x20>;
			xlnx,mask = <0xffffff80>;
			xlnx,use-io-bus = <0x01>;

			dummy_pmu_intc@0 {
				#interrupt-cells = <0x02>;
				interrupt-controller;
				phandle = <0x0e>;
			};

			pmu_gpo@10 {
				#gpio-cells = <0x02>;
				gpio-controller;
				compatible = "xlnx,io-gpo-1.02.a\0xlnx,io_gpo";
				reg = <0x00 0xffd40010 0x04>;
				xlnx,gpo-init = <0x00>;
				xlnx,gpo-size = <0x09>;
				xlnx,use-gpo = <0x01>;
				phandle = <0x5e>;
			};

			pmu_gpo@14 {
				#gpio-cells = <0x02>;
				gpio-controller;
				compatible = "xlnx,io-gpo-1.02.a\0xlnx,io_gpo";
				reg = <0x00 0xffd40014 0x04>;
				xlnx,gpo-init = <0x00>;
				xlnx,gpo-size = <0x20>;
				xlnx,use-gpo = <0x01>;
			};

			pmu_gpo@18 {
				#gpio-cells = <0x02>;
				gpio-controller;
				compatible = "xlnx,io-gpo-1.02.a\0xlnx,io_gpo";
				reg = <0x00 0xffd40018 0x04>;
				xlnx,gpo-init = <0x00>;
				xlnx,gpo-size = <0x20>;
				xlnx,use-gpo = <0x01>;
			};

			pmu_gpo@1c {
				#gpio-cells = <0x02>;
				gpio-controller;
				compatible = "xlnx,io-gpo-1.02.a\0xlnx,io_gpo";
				reg = <0x00 0xffd4001c 0x04>;
				xlnx,gpo-init = <0x00>;
				xlnx,gpo-size = <0x20>;
				xlnx,use-gpo = <0x01>;
			};

			pmu_gpi@20 {
				#gpio-cells = <0x02>;
				gpio-controller;
				compatible = "xlnx,io-gpi-1.02.a\0xlnx,io_gpi";
				interrupt-parent = <0x0e>;
				interrupts = <0x0b 0x00>;
				reg = <0x00 0xffd40020 0x04>;
				xlnx,gpi-interrupt = <0x01>;
				xlnx,gpi-size = <0x20>;
				xlnx,use-gpi = <0x01>;
			};

			pmu_gpi@24 {
				#gpio-cells = <0x02>;
				gpio-controller;
				compatible = "xlnx,io-gpi-1.02.a\0xlnx,io_gpi";
				interrupt-parent = <0x0e>;
				interrupts = <0x0c 0x00>;
				reg = <0x00 0xffd40024 0x04 0x00 0xffd60224 0x04>;
				xlnx,gpi-interrupt = <0x01>;
				xlnx,gpi-size = <0x20>;
				xlnx,use-gpi = <0x01>;
				gpios = <0x5c 0x00 0x00 0x5c 0x00 0x00 0x5c 0x00 0x00 0x5c 0x00 0x00 0x5c 0x00 0x00 0x5c 0x00 0x00 0x5c 0x00 0x00 0x5c 0x00 0x00 0x5c 0x00 0x00 0x5c 0x00 0x00 0x5d 0x1a 0x00 0x5d 0x1b 0x00 0x5d 0x1c 0x00 0x5d 0x1d 0x00 0x5d 0x1e 0x00 0x5d 0x1f 0x00>;
			};

			pmu_gpi@28 {
				#gpio-cells = <0x02>;
				gpio-controller;
				compatible = "xlnx,io-gpi-1.02.a\0xlnx,io_gpi";
				interrupt-parent = <0x0e>;
				interrupts = <0x0d 0x00>;
				reg = <0x00 0xffd40028 0x04 0x00 0xffd60228 0x04>;
				xlnx,gpi-interrupt = <0x01>;
				xlnx,gpi-size = <0x20>;
				xlnx,use-gpi = <0x01>;
			};

			pmu_gpi@2c {
				#gpio-cells = <0x02>;
				gpio-controller;
				compatible = "xlnx,io-gpi-1.02.a\0xlnx,io_gpi";
				interrupt-parent = <0x0e>;
				interrupts = <0x0e 0x00>;
				reg = <0x00 0xffd4002c 0x04>;
				xlnx,gpi-interrupt = <0x01>;
				xlnx,gpi-size = <0x20>;
				xlnx,use-gpi = <0x01>;
			};

			pmu_pit@40 {
				compatible = "xlnx,io-pit-1.02.a\0xlnx,io_pit";
				interrupt-parent = <0x0e>;
				interrupts = <0x03 0x00>;
				reg = <0x00 0xffd40040 0x0c>;
				xlnx,pit-interrupt = <0x01>;
				xlnx,pit-prescaler = <0x09>;
				xlnx,pit-readable = <0x01>;
				xlnx,pit-size = <0x20>;
				xlnx,use-pit = <0x01>;
				gpios = <0x5e 0x02 0x00 0x5f 0x00>;
				gpio-names = "ps_config\0ps_hit_in";
				gpio-controller;
				#gpio-cells = <0x01>;
			};

			pmu_pit@50 {
				compatible = "xlnx,io-pit-1.02.a\0xlnx,io_pit";
				interrupt-parent = <0x0e>;
				interrupts = <0x04 0x00>;
				reg = <0x00 0xffd40050 0x0c>;
				xlnx,pit-interrupt = <0x01>;
				xlnx,pit-prescaler = <0x09>;
				xlnx,pit-readable = <0x01>;
				xlnx,pit-size = <0x20>;
				xlnx,use-pit = <0x01>;
				gpio-controller;
				#gpio-cells = <0x01>;
				phandle = <0x5f>;
			};

			pmu_pit@60 {
				compatible = "xlnx,io-pit-1.02.a\0xlnx,io_pit";
				interrupt-parent = <0x0e>;
				interrupts = <0x05 0x00>;
				reg = <0x00 0xffd40060 0x0c>;
				xlnx,pit-interrupt = <0x01>;
				xlnx,pit-prescaler = <0x09>;
				xlnx,pit-readable = <0x01>;
				xlnx,pit-size = <0x20>;
				xlnx,use-pit = <0x01>;
				gpios = <0x5e 0x06 0x00 0x60 0x00>;
				gpio-names = "ps_config\0ps_hit_in";
				gpio-controller;
				#gpio-cells = <0x01>;
				phandle = <0x60>;
			};

			pmu_pit@70 {
				compatible = "xlnx,io-pit-1.02.a\0xlnx,io_pit";
				interrupt-parent = <0x0e>;
				interrupts = <0x06 0x00>;
				reg = <0x00 0xffd40070 0x0c>;
				xlnx,pit-interrupt = <0x01>;
				xlnx,pit-prescaler = <0x09>;
				xlnx,pit-readable = <0x01>;
				xlnx,pit-size = <0x20>;
				xlnx,use-pit = <0x01>;
				gpio-controller;
				#gpio-cells = <0x01>;
			};

			pmu_uart@00 {
				compatible = "xlnx,io-uart-1.02.a\0xlnx,io_uart";
				interrupt-parent = <0x0e>;
				interrupts = <0x00 0x00 0x01 0x00 0x02 0x00>;
				reg = <0x00 0xffd40000 0x0c 0x00 0xffd4004c 0x04>;
				xlnx,uart-baudrate = <0x2580>;
				xlnx,uart-data-bits = <0x08>;
				xlnx,uart-error-interrupt = <0x01>;
				xlnx,uart-odd-parity = <0x00>;
				xlnx,uart-prog-baudrate = <0x00>;
				xlnx,uart-rx-interrupt = <0x01>;
				xlnx,uart-tx-interrupt = <0x01>;
				xlnx,uart-use-parity = <0x00>;
				xlnx,use-uart-rx = <0x00>;
				xlnx,use-uart-tx = <0x00>;
			};

			dummy_pmu_gpio {
				#gpio-cells = <0x02>;
				gpio-controller;
				phandle = <0x5c>;
			};
		};

		pmu_local@ffd60000 {
			#gpio-cells = <0x01>;
			compatible = "xlnx,pmu-local";
			reg = <0x00 0xffd60000 0x00 0x1000 0x00>;
			gpio-controller;
			num-gpios = <0x07>;
		};
	};

	cpus {
		#address-cells = <0x01>;
		#size-cells = <0x00>;

		apu_cpu@0 {
			compatible = "cortex-a53-arm-cpu";
			d-cache-line-size = <0x20>;
			d-cache-size = <0x8000>;
			device_type = "cpu";
			i-cache-line-size = <0x20>;
			i-cache-size = <0x8000>;
			arm,midr = <0x410fd034>;
			arm,ctr = <0x83338003>;
			arm,clidr = <0x9200003>;
			arm,id_pfr0 = <0x1231>;
			arm,ccsidr0 = <0x701fe019>;
			arm,ccsidr1 = <0x201fe019>;
			arm,mp-affinity = <0x00>;
			enable-method = "psci";
			reg = <0x00>;
			core-count = <0x04>;
			arm,reset-hivecs = <0x01>;
			arm,rvbar = <0xffff0000>;
			#interrupt-cells = <0x01>;
			arm,reset-cbar = <0xfd3fe000>;
			mr = <0x61>;
			memory = <0x61>;
			gpios = <0x62 0x00>;
			gpio-names = "rst_cntrl";
			gdb-id = "Cortex-A53 #0";
			memattr_s = <0x63>;
			memattr_ns = <0x64>;
			phandle = <0x04>;
		};

		apu_cpu@1 {
			compatible = "cortex-a53-arm-cpu";
			d-cache-line-size = <0x20>;
			d-cache-size = <0x8000>;
			device_type = "cpu";
			i-cache-line-size = <0x20>;
			i-cache-size = <0x8000>;
			arm,midr = <0x410fd034>;
			arm,ctr = <0x83338003>;
			arm,clidr = <0x9200003>;
			arm,id_pfr0 = <0x1231>;
			arm,ccsidr0 = <0x701fe019>;
			arm,ccsidr1 = <0x201fe019>;
			arm,mp-affinity = <0x01>;
			enable-method = "psci";
			reg = <0x01>;
			core-count = <0x04>;
			arm,reset-hivecs = <0x01>;
			arm,rvbar = <0xffff0000>;
			#interrupt-cells = <0x01>;
			arm,reset-cbar = <0xfd3fe000>;
			mr = <0x61>;
			memory = <0x61>;
			gpios = <0x62 0x01>;
			gpio-names = "rst_cntrl";
			direct-lnx-start-powered-off = <0x01>;
			start-powered-off = <0x00>;
			gdb-id = "Cortex-A53 #1";
			memattr_s = <0x65>;
			memattr_ns = <0x66>;
			phandle = <0x05>;
		};

		apu_cpu@2 {
			compatible = "cortex-a53-arm-cpu";
			d-cache-line-size = <0x20>;
			d-cache-size = <0x8000>;
			device_type = "cpu";
			i-cache-line-size = <0x20>;
			i-cache-size = <0x8000>;
			arm,midr = <0x410fd034>;
			arm,ctr = <0x83338003>;
			arm,clidr = <0x9200003>;
			arm,id_pfr0 = <0x1231>;
			arm,ccsidr0 = <0x701fe019>;
			arm,ccsidr1 = <0x201fe019>;
			arm,mp-affinity = <0x02>;
			enable-method = "psci";
			reg = <0x02>;
			core-count = <0x04>;
			arm,reset-hivecs = <0x01>;
			arm,rvbar = <0xffff0000>;
			#interrupt-cells = <0x01>;
			arm,reset-cbar = <0xfd3fe000>;
			mr = <0x61>;
			memory = <0x61>;
			gpios = <0x62 0x02>;
			gpio-names = "rst_cntrl";
			direct-lnx-start-powered-off = <0x01>;
			start-powered-off = <0x00>;
			gdb-id = "Cortex-A53 #2";
			memattr_s = <0x67>;
			memattr_ns = <0x68>;
			phandle = <0x06>;
		};

		apu_cpu@3 {
			compatible = "cortex-a53-arm-cpu";
			d-cache-line-size = <0x20>;
			d-cache-size = <0x8000>;
			device_type = "cpu";
			i-cache-line-size = <0x20>;
			i-cache-size = <0x8000>;
			arm,midr = <0x410fd034>;
			arm,ctr = <0x83338003>;
			arm,clidr = <0x9200003>;
			arm,id_pfr0 = <0x1231>;
			arm,ccsidr0 = <0x701fe019>;
			arm,ccsidr1 = <0x201fe019>;
			arm,mp-affinity = <0x03>;
			enable-method = "psci";
			reg = <0x03>;
			core-count = <0x04>;
			arm,reset-hivecs = <0x01>;
			arm,rvbar = <0xffff0000>;
			#interrupt-cells = <0x01>;
			arm,reset-cbar = <0xfd3fe000>;
			mr = <0x61>;
			memory = <0x61>;
			gpios = <0x62 0x03>;
			gpio-names = "rst_cntrl";
			direct-lnx-start-powered-off = <0x01>;
			start-powered-off = <0x00>;
			gdb-id = "Cortex-A53 #3";
			memattr_s = <0x69>;
			memattr_ns = <0x6a>;
			phandle = <0x07>;
		};

		rpu_cpu@0 {
			compatible = "cortex-r5f-arm-cpu";
			d-cache-line-size = <0x20>;
			d-cache-size = <0x8000>;
			device_type = "cpu";
			i-cache-line-size = <0x20>;
			i-cache-size = <0x8000>;
			arm,midr = <0x411fc153>;
			arm,tcmtr = <0x10001>;
			arm,ctr = <0x8003c003>;
			arm,clidr = <0x9200003>;
			arm,ccsidr0 = <0xf01fe019>;
			arm,ccsidr1 = <0xf01fe019>;
			arm,mp-affinity = <0x100>;
			arm,id_pfr0 = <0x131>;
			arm,reset-hivecs = <0x01>;
			#interrupt-cells = <0x01>;
			reg = <0x00>;
			mr = <0x6b>;
			memory = <0x6b>;
			gpios = <0x4f 0x00 0x6c 0x00 0x6c 0x05>;
			gpio-names = "reset\0ncpuhalt\0vinithi";
			gdb-id = "Cortex-R5 #0";
			memattr_ns = <0x6d>;
			phandle = <0x72>;
		};

		rpu_cpu@1 {
			compatible = "cortex-r5f-arm-cpu";
			d-cache-line-size = <0x20>;
			d-cache-size = <0x8000>;
			device_type = "cpu";
			i-cache-line-size = <0x20>;
			i-cache-size = <0x8000>;
			arm,midr = <0x411fc153>;
			arm,tcmtr = <0x10001>;
			arm,ctr = <0x8003c003>;
			arm,clidr = <0x9200003>;
			arm,ccsidr0 = <0xf01fe019>;
			arm,ccsidr1 = <0xf01fe019>;
			arm,mp-affinity = <0x101>;
			arm,id_pfr0 = <0x131>;
			arm,reset-hivecs = <0x01>;
			#interrupt-cells = <0x01>;
			reg = <0x01>;
			mr = <0x6e>;
			memory = <0x6e>;
			gpios = <0x4f 0x01 0x6c 0x02 0x6c 0x01 0x6c 0x06>;
			gpio-names = "reset\0halt\0ncpuhalt\0vinithi";
			gdb-id = "Cortex-R5 #1";
			memattr_ns = <0x6f>;
			phandle = <0x73>;
		};
	};

	aliases {
		serial0 = "/amba@0/serial@0xFF000000";
		serial1 = "/amba@0/serial@0xFF010000";
		ethernet0 = "/amba@0/gem3@0";

		main_bus_for_apu {
			compatible = "qemu:memory-region";
			container = <0x61>;
			alias = <0x23>;
			priority = <0xffffffff>;
		};

		main_bus_for_pl {
			compatible = "qemu:memory-region";
			container = <0x1a>;
			alias = <0x70>;
			priority = <0xffffffff>;
		};
	};

	amba_apu@0 {
		#address-cells = <0x02>;
		#size-cells = <0x01>;
		compatible = "xlnx,ps7-axi-interconnect-1.00.a\0simple-bus";
		ranges;
		phandle = <0x61>;

		timer {
			compatible = "arm,armv8-timer";
			interrupt-parent = <0x02>;
			interrupts = <0x01 0x0d 0xff01 0x01 0x0e 0xff01 0x01 0x0b 0xff01 0x01 0x0a 0xff01>;
			clock-frequency = <0x5f5e100>;
		};

		dymmy@0 {
			interrupt-controller;
			#interrupt-cells = <0x01>;
			phandle = <0x71>;
		};
	};

	amba_apu_gic@0 {
		#address-cells = <0x02>;
		#priority-cells = <0x01>;
		#size-cells = <0x01>;
		compatible = "xlnx,ps7-axi-interconnect-1.00.a\0simple-bus";
		ranges;
		container = <0x1a>;
		priority = <0xffffffff>;

		interrupt-controller@0xFD3FF000 {
			#address-cells = <0x00>;
			#size-cells = <0x00>;
			#interrupt-cells = <0x03>;
			#gpio-cells = <0x00>;
			compatible = "xlnx,zynqmp-scugic\0arm,gic";
			reg = <0x00 0xf9010000 0x1000 0x00 0x00 0xf9020000 0x20000 0x00 0x00 0xf9040000 0x20000 0x00 0x00 0xf9060000 0x20000 0x00>;
			interrupt-controller;
			num-irq = <0xc0>;
			interrupts-extended = <0x04 0x00 0x05 0x00 0x06 0x00 0x07 0x00 0x71 0x00 0x71 0x00 0x71 0x00 0x71 0x00 0x04 0x02 0x05 0x02 0x06 0x02 0x07 0x02 0x71 0x00 0x71 0x00 0x71 0x00 0x71 0x00 0x04 0x01 0x05 0x01 0x06 0x01 0x07 0x01 0x71 0x00 0x71 0x00 0x71 0x00 0x71 0x00 0x04 0x03 0x05 0x03 0x06 0x03 0x07 0x03 0x71 0x00 0x71 0x00 0x71 0x00 0x71 0x00 0x02 0x01 0x09 0x104 0x02 0x01 0x09 0x204 0x02 0x01 0x09 0x404 0x02 0x01 0x09 0x804>;
			num-cpu = <0x04>;
			revision = <0x02>;
			has-security-extensions = <0x01>;
			int-id = <0x202143b>;
			phandle = <0x02>;
		};

		zynqmp-gic-cpu-alias@0xf9021000 {
			compatible = "qemu:memory-region";
			alias = <0x02 0x01>;
			reg = <0x00 0xf9021000 0x1000 0x01>;
		};

		zynqmp-gic-cpu-alias@0xf9022000 {
			compatible = "qemu:memory-region";
			alias = <0x02 0x01>;
			reg = <0x00 0xf9022000 0x1000 0x01>;
		};

		zynqmp-gic-cpu-alias@0xf9023000 {
			compatible = "qemu:memory-region";
			alias = <0x02 0x01>;
			reg = <0x00 0xf9023000 0x1000 0x01>;
		};

		zynqmp-gic-cpu-alias@0xf9024000 {
			compatible = "qemu:memory-region";
			alias = <0x02 0x01>;
			reg = <0x00 0xf9024000 0x1000 0x01>;
		};

		zynqmp-gic-cpu-alias@0xf9025000 {
			compatible = "qemu:memory-region";
			alias = <0x02 0x01>;
			reg = <0x00 0xf9025000 0x1000 0x01>;
		};

		zynqmp-gic-cpu-alias@0xf9026000 {
			compatible = "qemu:memory-region";
			alias = <0x02 0x01>;
			reg = <0x00 0xf9026000 0x1000 0x01>;
		};

		zynqmp-gic-cpu-alias@0xf9027000 {
			compatible = "qemu:memory-region";
			alias = <0x02 0x01>;
			reg = <0x00 0xf9027000 0x1000 0x01>;
		};

		zynqmp-gic-cpu-alias@0xf9028000 {
			compatible = "qemu:memory-region";
			alias = <0x02 0x01>;
			reg = <0x00 0xf9028000 0x1000 0x01>;
		};

		zynqmp-gic-cpu-alias@0xf9029000 {
			compatible = "qemu:memory-region";
			alias = <0x02 0x01>;
			reg = <0x00 0xf9029000 0x1000 0x01>;
		};

		zynqmp-gic-cpu-alias@0xf902a000 {
			compatible = "qemu:memory-region";
			alias = <0x02 0x01>;
			reg = <0x00 0xf902a000 0x1000 0x01>;
		};

		zynqmp-gic-cpu-alias@0xf902b000 {
			compatible = "qemu:memory-region";
			alias = <0x02 0x01>;
			reg = <0x00 0xf902b000 0x1000 0x01>;
		};

		zynqmp-gic-cpu-alias@0xf902c000 {
			compatible = "qemu:memory-region";
			alias = <0x02 0x01>;
			reg = <0x00 0xf902c000 0x1000 0x01>;
		};

		zynqmp-gic-cpu-alias@0xf902d000 {
			compatible = "qemu:memory-region";
			alias = <0x02 0x01>;
			reg = <0x00 0xf902d000 0x1000 0x01>;
		};

		zynqmp-gic-cpu-alias@0xf902e000 {
			compatible = "qemu:memory-region";
			alias = <0x02 0x01>;
			reg = <0x00 0xf902e000 0x1000 0x01>;
		};

		zynqmp-gic-cpu-alias@0xf902f000 {
			compatible = "qemu:memory-region";
			alias = <0x02 0x01>;
			reg = <0x00 0xf902f000 0x2000 0x01>;
		};

		zynqmp-gic-vcpu-alias@0xf9061000 {
			compatible = "qemu:memory-region";
			alias = <0x02 0x03>;
			reg = <0x00 0xf9061000 0x1000 0x01>;
		};

		zynqmp-gic-vcpu-alias@0xf9062000 {
			compatible = "qemu:memory-region";
			alias = <0x02 0x03>;
			reg = <0x00 0xf9062000 0x1000 0x01>;
		};

		zynqmp-gic-vcpu-alias@0xf9063000 {
			compatible = "qemu:memory-region";
			alias = <0x02 0x03>;
			reg = <0x00 0xf9063000 0x1000 0x01>;
		};

		zynqmp-gic-vcpu-alias@0xf9064000 {
			compatible = "qemu:memory-region";
			alias = <0x02 0x03>;
			reg = <0x00 0xf9064000 0x1000 0x01>;
		};

		zynqmp-gic-vcpu-alias@0xf9065000 {
			compatible = "qemu:memory-region";
			alias = <0x02 0x03>;
			reg = <0x00 0xf9065000 0x1000 0x01>;
		};

		zynqmp-gic-vcpu-alias@0xf9066000 {
			compatible = "qemu:memory-region";
			alias = <0x02 0x03>;
			reg = <0x00 0xf9066000 0x1000 0x01>;
		};

		zynqmp-gic-vcpu-alias@0xf9067000 {
			compatible = "qemu:memory-region";
			alias = <0x02 0x03>;
			reg = <0x00 0xf9067000 0x1000 0x01>;
		};

		zynqmp-gic-vcpu-alias@0xf9068000 {
			compatible = "qemu:memory-region";
			alias = <0x02 0x03>;
			reg = <0x00 0xf9068000 0x1000 0x01>;
		};

		zynqmp-gic-vcpu-alias@0xf9069000 {
			compatible = "qemu:memory-region";
			alias = <0x02 0x03>;
			reg = <0x00 0xf9069000 0x1000 0x01>;
		};

		zynqmp-gic-vcpu-alias@0xf906a000 {
			compatible = "qemu:memory-region";
			alias = <0x02 0x03>;
			reg = <0x00 0xf906a000 0x1000 0x01>;
		};

		zynqmp-gic-vcpu-alias@0xf906b000 {
			compatible = "qemu:memory-region";
			alias = <0x02 0x03>;
			reg = <0x00 0xf906b000 0x1000 0x01>;
		};

		zynqmp-gic-vcpu-alias@0xf906c000 {
			compatible = "qemu:memory-region";
			alias = <0x02 0x03>;
			reg = <0x00 0xf906c000 0x1000 0x01>;
		};

		zynqmp-gic-vcpu-alias@0xf906d000 {
			compatible = "qemu:memory-region";
			alias = <0x02 0x03>;
			reg = <0x00 0xf906d000 0x1000 0x01>;
		};

		zynqmp-gic-vcpu-alias@0xf906e000 {
			compatible = "qemu:memory-region";
			alias = <0x02 0x03>;
			reg = <0x00 0xf906e000 0x1000 0x01>;
		};

		zynqmp-gic-vcpu-alias@0xf906f000 {
			compatible = "qemu:memory-region";
			alias = <0x02 0x03>;
			reg = <0x00 0xf906f000 0x2000 0x01>;
		};
	};

	amba_rpu@0 {
		#address-cells = <0x02>;
		#size-cells = <0x02>;
		#priority-cells = <0x01>;
		compatible = "xlnx,ps7-axi-interconnect-1.00.a\0simple-bus";
		ranges;
		phandle = <0x2a>;

		interrupt-controller@0xF9000000 {
			#address-cells = <0x00>;
			#interrupt-cells = <0x03>;
			#size-cells = <0x00>;
			compatible = "xlnx,zynqmp-scugic\0arm,gic";
			reg = <0x00 0xf9000000 0x00 0x1000 0x00 0x00 0xf9001000 0x00 0x100 0x00>;
			status = "disabled";
			interrupt-controller;
			num-irq = <0x100>;
			num-cpu = <0x02>;
			interrupts-extended = <0x72 0x00 0x73 0x00>;
			phandle = <0x03>;
		};

		ddr_memory_2_for_rpu {
			compatible = "qemu:memory-region";
			alias = <0x74>;
			reg = <0x00 0x30000 0x00 0x10000 0x00>;
			phandle = <0x0d>;
		};

		main_bus_for_rpu {
			compatible = "qemu:memory-region";
			alias = <0x1b>;
			reg = <0x00 0x00 0xffffffff 0xffffffff 0xffffffff>;
		};
	};

	tbu0_slave@0 {
		#address-cells = <0x02>;
		#size-cells = <0x02>;
		compatible = "simple-bus";
		ranges;
		phandle = <0x1c>;
	};

	tbu1_slave@0 {
		#address-cells = <0x02>;
		#size-cells = <0x02>;
		compatible = "simple-bus";
		ranges;
		phandle = <0x1d>;
	};

	tbu2_slave@0 {
		#address-cells = <0x02>;
		#size-cells = <0x02>;
		compatible = "simple-bus";
		ranges;
		phandle = <0x1e>;
	};

	tbu3_slave@0 {
		#address-cells = <0x02>;
		#size-cells = <0x02>;
		compatible = "simple-bus";
		ranges;
		phandle = <0x1f>;
	};

	tbu4_slave@0 {
		#address-cells = <0x02>;
		#size-cells = <0x02>;
		compatible = "simple-bus";
		ranges;
		phandle = <0x20>;
	};

	tbu5_slave@0 {
		#address-cells = <0x02>;
		#size-cells = <0x02>;
		compatible = "simple-bus";
		ranges;
		phandle = <0x21>;
	};

	tbu3_master@0 {
		#address-cells = <0x02>;
		#size-cells = <0x02>;
		#priority-cells = <0x01>;
		compatible = "simple-bus";
		ranges;
		phandle = <0x24>;

		main_bus_for_tbu3 {
			compatible = "qemu:memory-region";
			alias = <0x1b>;
			reg = <0x00 0x00 0xffffffff 0xffffffff 0xffffffff>;
		};
	};

	tbu4_master@0 {
		#address-cells = <0x02>;
		#size-cells = <0x02>;
		#priority-cells = <0x01>;
		compatible = "simple-bus";
		ranges;
		phandle = <0x25>;

		main_bus_for_tbu4 {
			compatible = "qemu:memory-region";
			alias = <0x1b>;
			reg = <0x00 0x00 0xffffffff 0xffffffff 0xffffffff>;
		};
	};

	tbu5_master@0 {
		#address-cells = <0x02>;
		#size-cells = <0x02>;
		#priority-cells = <0x01>;
		compatible = "simple-bus";
		ranges;
		phandle = <0x26>;

		main_bus_for_tbu5 {
			compatible = "qemu:memory-region";
			alias = <0x1b>;
			reg = <0x00 0x00 0xffffffff 0xffffffff 0xffffffff>;
		};
	};

	cci_slave@0 {
		#address-cells = <0x02>;
		#size-cells = <0x02>;
		#priority-cells = <0x01>;
		compatible = "simple-bus";
		ranges;
		phandle = <0x23>;

		downstream {
			compatible = "qemu:memory-region";
			alias = <0x1b>;
			reg = <0x00 0x00 0xffffffff 0xffffffff 0x01>;
		};
	};

	amba_prio@0 {
		#address-cells = <0x02>;
		#size-cells = <0x02>;
		#priority-cells = <0x01>;
		compatible = "qemu:memory-region";
		phandle = <0x2c>;

		csu_stream_switch@ffcc0200 {
			compatible = "zynqmp,csu-sss";
			reg = <0x00 0xffca0008 0x00 0x04 0x00>;
			stream-connected-dma = <0x75>;
			stream-connected-pcap = <0x76>;
			stream-connected-aes = <0x56>;
			stream-connected-sha = <0x77>;
			phandle = <0x54>;
		};

		csu_pcap@0xFFCA3000 {
			compatible = "zynqmp,csu-pcap";
			reg = <0x00 0xffca3000 0x00 0x10000 0x00>;
			stream-connected-pcap = <0x54>;
			phandle = <0x76>;
		};

		loader_write_cpu0_0x1003F@0xFD0807E0 {
			compatible = "loader";
			addr = <0xfd0807e0>;
			data = <0x1003f>;
			data-len = <0x04>;
			cpu-num = <0x00>;
			attrs-debug = <0x01>;
			attrs-secure = <0x00>;
			attrs-requester-id = <0x00>;
		};

		loader_write_cpu0_0x1003F@0xFD0809E0 {
			compatible = "loader";
			addr = <0xfd0809e0>;
			data = <0x1003f>;
			data-len = <0x04>;
			cpu-num = <0x00>;
			attrs-debug = <0x01>;
			attrs-secure = <0x00>;
			attrs-requester-id = <0x00>;
		};

		loader_write_cpu0_0x1003F@0xFD080BE0 {
			compatible = "loader";
			addr = <0xfd080be0>;
			data = <0x1003f>;
			data-len = <0x04>;
			cpu-num = <0x00>;
			attrs-debug = <0x01>;
			attrs-secure = <0x00>;
			attrs-requester-id = <0x00>;
		};

		loader_write_cpu0_0x1003F@0xFD080DE0 {
			compatible = "loader";
			addr = <0xfd080de0>;
			data = <0x1003f>;
			data-len = <0x04>;
			cpu-num = <0x00>;
			attrs-debug = <0x01>;
			attrs-secure = <0x00>;
			attrs-requester-id = <0x00>;
		};
	};

	misc_clk {
		#clock-cells = <0x00>;
		clock-frequency = <0x2faf080>;
		compatible = "fixed-clock";
		phandle = <0x41>;
	};

	pcie_ingress@0 {
		#address-cells = <0x02>;
		#size-cells = <0x02>;
		#priority-cells = <0x01>;
		compatible = "simple-bus";
		phandle = <0x50>;

		downstream {
			compatible = "qemu:memory-region";
			alias = <0x1d>;
			reg = <0x00 0x00 0xffffffff 0xffffffff 0xffffffff>;
		};
	};

	pcie_overlay@0 {
		#address-cells = <0x02>;
		#size-cells = <0x02>;
		#priority-cells = <0x01>;
		priority = <0x02>;
		compatible = "qemu:memory-region";
		container = <0x1a>;
		phandle = <0x51>;
	};

	ddr_alias@0 {
		compatible = "qemu:memory-region";
		container = <0x78>;
		alias = <0x01>;
		reg = <0x00 0x00 0xffffffff 0xffffffff 0x00>;
	};

	qemu_sysmem@0 {
		#address-cells = <0x02>;
		#size-cells = <0x02>;
		#priority-cells = <0x01>;
		compatible = "qemu:system-memory";
		phandle = <0x78>;
	};

	pmu_ma {
		compatible = "qemu:memory-transaction-attr";
		secure = <0x01>;
		requester-id = <0x40>;
	};

	apu0_s_ma {
		compatible = "qemu:memory-transaction-attr";
		secure = <0x01>;
		requester-id = <0x80>;
		phandle = <0x63>;
	};

	apu0_ns_ma {
		compatible = "qemu:memory-transaction-attr";
		secure = <0x00>;
		requester-id = <0x80>;
		phandle = <0x64>;
	};

	apu1_s_ma {
		compatible = "qemu:memory-transaction-attr";
		secure = <0x01>;
		requester-id = <0x8d>;
		phandle = <0x65>;
	};

	apu1_ns_ma {
		compatible = "qemu:memory-transaction-attr";
		secure = <0x00>;
		requester-id = <0x8d>;
		phandle = <0x66>;
	};

	apu2_s_ma {
		compatible = "qemu:memory-transaction-attr";
		secure = <0x01>;
		requester-id = <0x8e>;
		phandle = <0x67>;
	};

	apu2_ns_ma {
		compatible = "qemu:memory-transaction-attr";
		secure = <0x00>;
		requester-id = <0x8e>;
		phandle = <0x68>;
	};

	apu3_s_ma {
		compatible = "qemu:memory-transaction-attr";
		secure = <0x01>;
		requester-id = <0x8f>;
		phandle = <0x69>;
	};

	apu3_ns_ma {
		compatible = "qemu:memory-transaction-attr";
		secure = <0x00>;
		requester-id = <0x8f>;
		phandle = <0x6a>;
	};

	rpu0_ma {
		compatible = "qemu:memory-transaction-attr";
		secure = <0x01>;
		requester-id = <0x2e>;
		phandle = <0x6d>;
	};

	rpu1_ma {
		compatible = "qemu:memory-transaction-attr";
		secure = <0x01>;
		requester-id = <0x2f>;
		phandle = <0x6f>;
	};

	gem0_ma {
		compatible = "qemu:memory-transaction-attr";
		secure = <0x00>;
		requester-id = <0x874>;
		phandle = <0x3a>;
	};

	gem1_ma {
		compatible = "qemu:memory-transaction-attr";
		secure = <0x00>;
		requester-id = <0x875>;
		phandle = <0x3b>;
	};

	gem2_ma {
		compatible = "qemu:memory-transaction-attr";
		secure = <0x00>;
		requester-id = <0x876>;
		phandle = <0x3c>;
	};

	gem3_ma {
		compatible = "qemu:memory-transaction-attr";
		secure = <0x00>;
		requester-id = <0x877>;
		phandle = <0x3d>;
	};

	qspi_dma_ma {
		compatible = "qemu:memory-transaction-attr";
		secure = <0x00>;
		requester-id = <0x873>;
		phandle = <0x3f>;
	};

	sd0_ma {
		compatible = "qemu:memory-transaction-attr";
		secure = <0x00>;
		requester-id = <0x870>;
		phandle = <0x43>;
	};

	sd1_ma {
		compatible = "qemu:memory-transaction-attr";
		secure = <0x00>;
		requester-id = <0x871>;
		phandle = <0x45>;
	};

	pcie_ns_ma {
		compatible = "qemu:memory-transaction-attr";
		secure = <0x00>;
		requester-id = <0x4d0>;
		phandle = <0x52>;
	};

	csu_dma_ma {
		compatible = "qemu:memory-transaction-attr";
		secure = <0x00>;
		requester-id = <0x851>;
		phandle = <0x53>;
	};

	protected_amba@0 {
		#address-cells = <0x02>;
		#size-cells = <0x02>;
		#priority-cells = <0x01>;
		compatible = "xlnx,ps7-axi-interconnect-1.00.a\0simple-bus";
		ranges;
		phandle = <0x1b>;

		downstream {
			compatible = "qemu:memory-region";
			alias = <0x1a>;
			reg = <0x00 0x00 0xffffffff 0xffffffff 0xffffffff>;
		};
	};

	memory@00000000 {
		compatible = "qemu:memory-region";
		device_type = "memory";
		container = <0x1a>;
		phandle = <0x01>;
	};

	pmu_ram@ffdc0000 {
		compatible = "qemu:memory-region";
		container = <0x1a>;
		qemu,ram = <0x01>;
		reg = <0x00 0xffdc0000 0x20000>;
	};

	tcm_ram_r5_0_A@0x00000 {
		compatible = "qemu:memory-region";
		container = <0x59>;
		qemu,ram = <0x01>;
		reg = <0x00 0x00 0x10000>;
	};

	tcm_ram_r5_0_B@0x20000 {
		compatible = "qemu:memory-region";
		container = <0x59>;
		qemu,ram = <0x01>;
		reg = <0x00 0x20000 0x10000>;
	};

	tcm_ram_r5_1_A@0x00000 {
		compatible = "qemu:memory-region";
		container = <0x5a>;
		qemu,ram = <0x01>;
		reg = <0x00 0x00 0x10000>;
		phandle = <0x79>;
	};

	tcm_ram_r5_1_B@0x20000 {
		compatible = "qemu:memory-region";
		container = <0x5a>;
		qemu,ram = <0x01>;
		reg = <0x00 0x20000 0x10000>;
		phandle = <0x7a>;
	};

	icache_rpu0@0x40000 {
		compatible = "qemu:memory-region";
		container = <0x59>;
		qemu,ram = <0x01>;
		reg = <0x00 0x40000 0x8000>;
	};

	dcache_rpu0@0x50000 {
		compatible = "qemu:memory-region";
		container = <0x59>;
		qemu,ram = <0x01>;
		reg = <0x00 0x50000 0x8000>;
	};

	icache_rpu1@0x30000 {
		compatible = "qemu:memory-region";
		container = <0x5a>;
		qemu,ram = <0x01>;
		reg = <0x00 0x30000 0x8000>;
		phandle = <0x0a>;
	};

	dcache_rpu1@0x40000 {
		compatible = "qemu:memory-region";
		container = <0x5a>;
		qemu,ram = <0x01>;
		reg = <0x00 0x40000 0x8000>;
		phandle = <0x0b>;
	};

	ipibuf@ff990000 {
		compatible = "qemu:memory-region";
		container = <0x1a>;
		qemu,ram = <0x01>;
		reg = <0x00 0xff990000 0x1000>;
	};

	ocm_ram@0 {
		compatible = "qemu:memory-region";
		phandle = <0x29>;
	};

	ocm_ram_bank_0@0x00000 {
		compatible = "qemu:memory-region";
		container = <0x29>;
		qemu,ram = <0x01>;
		reg = <0x00 0x00 0x10000>;
	};

	ocm_ram_bank_1@0x10000 {
		compatible = "qemu:memory-region";
		container = <0x29>;
		qemu,ram = <0x01>;
		reg = <0x00 0x10000 0x10000>;
	};

	ocm_ram_bank_2@0x20000 {
		compatible = "qemu:memory-region";
		container = <0x29>;
		qemu,ram = <0x01>;
		reg = <0x00 0x20000 0x10000>;
	};

	ocm_ram_bank_3@0x30000 {
		compatible = "qemu:memory-region";
		container = <0x29>;
		qemu,ram = <0x01>;
		reg = <0x00 0x30000 0x10000>;
	};

	tcm_cache_rpu0@0 {
		#address-cells = <0x02>;
		#size-cells = <0x02>;
		#priority-cells = <0x01>;
		compatible = "qemu:memory-region";
		phandle = <0x59>;

		atcm1_for_rpu0 {
			compatible = "qemu:memory-region";
			alias = <0x79>;
			reg = <0x00 0x10000 0x00 0x10000 0x01>;
			phandle = <0x08>;
		};

		btcm1_for_rpu0 {
			compatible = "qemu:memory-region";
			alias = <0x7a>;
			reg = <0x00 0x30000 0x00 0x10000 0x01>;
			phandle = <0x09>;
		};
	};

	amba_rpu0@0 {
		#address-cells = <0x02>;
		#size-cells = <0x02>;
		#priority-cells = <0x01>;
		compatible = "xlnx,ps7-axi-interconnect-1.00.a\0simple-bus";
		ranges;
		phandle = <0x6b>;

		tcm_cache_rpu0 {
			compatible = "qemu:memory-region";
			alias = <0x59>;
			reg = <0x00 0x00 0xffffffff 0xffffffff 0x00>;
		};

		rpu_bus_for_rpu0 {
			compatible = "qemu:memory-region";
			alias = <0x2a>;
			reg = <0x00 0x00 0xffffffff 0xffffffff 0xffffffff>;
		};
	};

	tcm_cache_rpu1@0 {
		#address-cells = <0x02>;
		#size-cells = <0x02>;
		#priority-cells = <0x01>;
		compatible = "qemu:memory-region";
		phandle = <0x5a>;
	};

	amba_rpu1@0 {
		#address-cells = <0x02>;
		#size-cells = <0x02>;
		#priority-cells = <0x01>;
		compatible = "xlnx,ps7-axi-interconnect-1.00.a\0simple-bus";
		ranges;
		phandle = <0x6e>;

		tcm_cache_rpu1 {
			compatible = "qemu:memory-region";
			alias = <0x5a>;
			reg = <0x00 0x00 0xffffffff 0xffffffff 0x01>;
		};

		rpu_bus_for_rpu1 {
			compatible = "qemu:memory-region";
			alias = <0x2a>;
			reg = <0x00 0x00 0xffffffff 0xffffffff 0xffffffff>;
		};
	};

	amba_pl {
		#address-cells = <0x02>;
		#size-cells = <0x02>;
		compatible = "simple-bus";
		ranges;
		phandle = <0x70>;
	};

	mdio {
		#address-cells = <0x01>;
		#size-cells = <0x00>;
		compatible = "mdio";
		phandle = <0x3e>;

		phy@7 {
			compatible = "88e1118r";
			device_type = "ethernet-phy";
		};
	};
};
